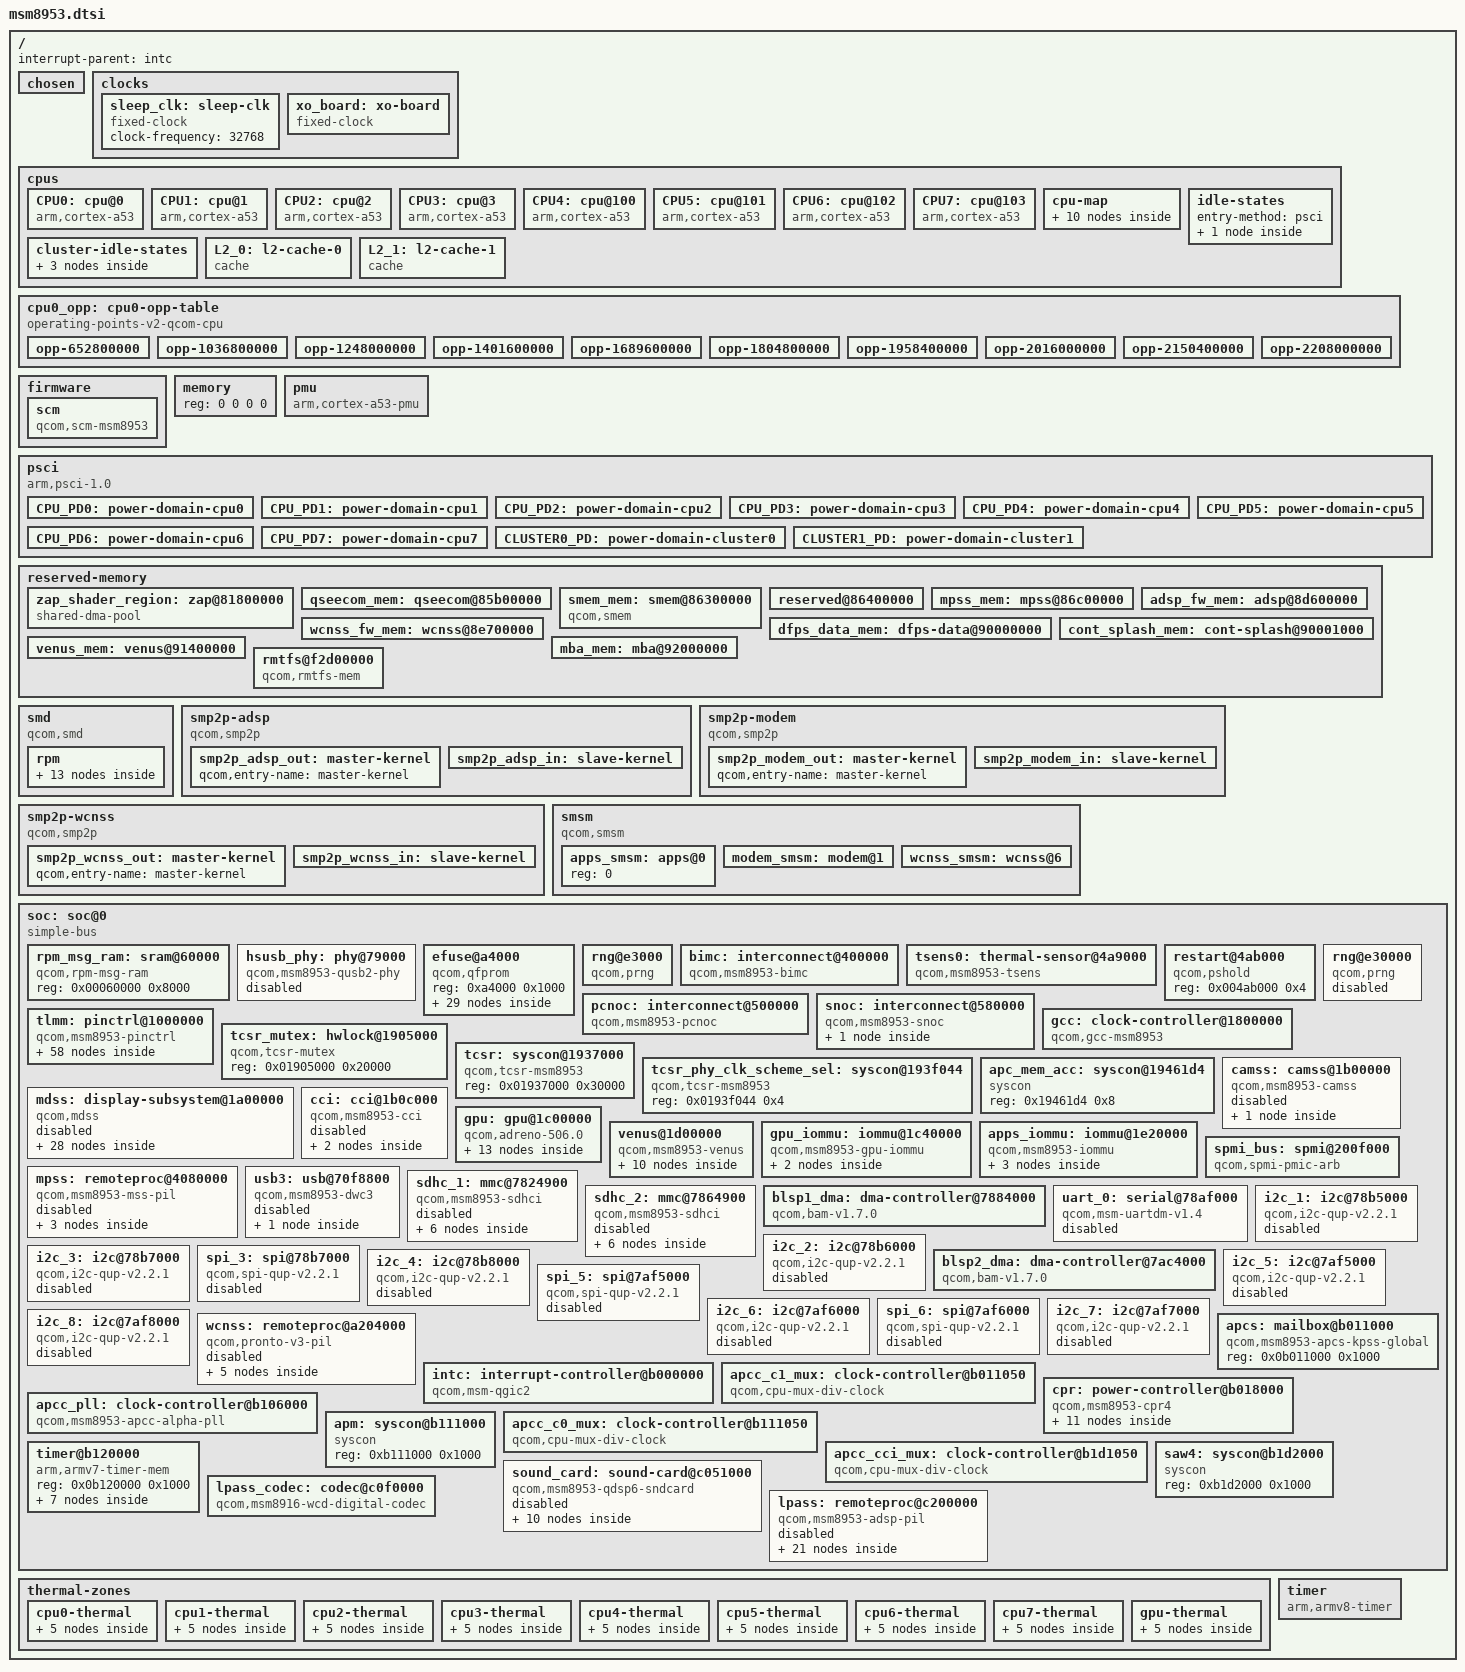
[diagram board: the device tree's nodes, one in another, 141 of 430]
// SPDX-License-Identifier: BSD-3-Clause
/* Copyright (c) 2022, The Linux Foundation. All rights reserved. */

#include <dt-bindings/clock/qcom,gcc-msm8953.h>
#include <dt-bindings/clock/qcom,rpmcc.h>
#include <dt-bindings/gpio/gpio.h>
#include <dt-bindings/interconnect/qcom,msm8953.h>
#include <dt-bindings/interrupt-controller/arm-gic.h>
#include <dt-bindings/power/qcom-rpmpd.h>
#include <dt-bindings/soc/qcom,apr.h>
#include <dt-bindings/sound/qcom,q6afe.h>
#include <dt-bindings/sound/qcom,q6asm.h>
#include <dt-bindings/sound/qcom,q6voice.h>
#include <dt-bindings/thermal/thermal.h>

/ {
	interrupt-parent = <&intc>;

	#address-cells = <2>;
	#size-cells = <2>;

	chosen { };

	clocks {
		sleep_clk: sleep-clk {
			compatible = "fixed-clock";
			#clock-cells = <0>;
			clock-frequency = <32768>;
		};

		xo_board: xo-board {
			compatible = "fixed-clock";
			#clock-cells = <0>;
			clock-frequency = <19200000>;
			clock-output-names = "xo";
		};
	};

	cpus {
		#address-cells = <1>;
		#size-cells = <0>;

		CPU0: cpu@0 {
			device_type = "cpu";
			compatible = "arm,cortex-a53";
			reg = <0x0>;
			enable-method = "psci";
			capacity-dmips-mhz = <1024>;
			clocks = <&apcc_pll>;
			clock-names = "cpu";
			operating-points-v2 = <&cpu0_opp>;
			power-domains = <&CPU_PD0>, <&cpr 0>;
			power-domain-names = "psci", "cpr";
			interconnects = <&bimc MAS_APPS_PROC &bimc SLV_EBI>;
			next-level-cache = <&L2_0>;
			#cooling-cells = <2>;
		};

		CPU1: cpu@1 {
			device_type = "cpu";
			compatible = "arm,cortex-a53";
			reg = <0x1>;
			enable-method = "psci";
			capacity-dmips-mhz = <1024>;
			clocks = <&apcc_pll>;
			clock-names = "cpu";
			operating-points-v2 = <&cpu0_opp>;
			power-domains = <&CPU_PD1>, <&cpr 0>;
			power-domain-names = "psci", "cpr";
			interconnects = <&bimc MAS_APPS_PROC &bimc SLV_EBI>;
			next-level-cache = <&L2_0>;
			#cooling-cells = <2>;
		};

		CPU2: cpu@2 {
			device_type = "cpu";
			compatible = "arm,cortex-a53";
			reg = <0x2>;
			enable-method = "psci";
			capacity-dmips-mhz = <1024>;
			clocks = <&apcc_pll>;
			clock-names = "cpu";
			operating-points-v2 = <&cpu0_opp>;
			power-domains = <&CPU_PD2>, <&cpr 0>;
			power-domain-names = "psci", "cpr";
			interconnects = <&bimc MAS_APPS_PROC &bimc SLV_EBI>;
			next-level-cache = <&L2_0>;
			#cooling-cells = <2>;
		};

		CPU3: cpu@3 {
			device_type = "cpu";
			compatible = "arm,cortex-a53";
			reg = <0x3>;
			enable-method = "psci";
			capacity-dmips-mhz = <1024>;
			clocks = <&apcc_pll>;
			clock-names = "cpu";
			operating-points-v2 = <&cpu0_opp>;
			power-domains = <&CPU_PD3>, <&cpr 0>;
			power-domain-names = "psci", "cpr";
			interconnects = <&bimc MAS_APPS_PROC &bimc SLV_EBI>;
			next-level-cache = <&L2_0>;
			#cooling-cells = <2>;
		};

		CPU4: cpu@100 {
			device_type = "cpu";
			compatible = "arm,cortex-a53";
			reg = <0x100>;
			enable-method = "psci";
			capacity-dmips-mhz = <1024>;
			clocks = <&apcc_pll>;
			clock-names = "cpu";
			operating-points-v2 = <&cpu0_opp>;
			power-domains = <&CPU_PD4>, <&cpr 0>;
			power-domain-names = "psci", "cpr";
			interconnects = <&bimc MAS_APPS_PROC &bimc SLV_EBI>;
			next-level-cache = <&L2_1>;
			#cooling-cells = <2>;
		};

		CPU5: cpu@101 {
			device_type = "cpu";
			compatible = "arm,cortex-a53";
			reg = <0x101>;
			enable-method = "psci";
			capacity-dmips-mhz = <1024>;
			clocks = <&apcc_pll>;
			clock-names = "cpu";
			operating-points-v2 = <&cpu0_opp>;
			power-domains = <&CPU_PD5>, <&cpr 0>;
			power-domain-names = "psci", "cpr";
			interconnects = <&bimc MAS_APPS_PROC &bimc SLV_EBI>;
			next-level-cache = <&L2_1>;
			#cooling-cells = <2>;
		};

		CPU6: cpu@102 {
			device_type = "cpu";
			compatible = "arm,cortex-a53";
			reg = <0x102>;
			enable-method = "psci";
			capacity-dmips-mhz = <1024>;
			clocks = <&apcc_pll>;
			clock-names = "cpu";
			operating-points-v2 = <&cpu0_opp>;
			power-domains = <&CPU_PD6>, <&cpr 0>;
			power-domain-names = "psci", "cpr";
			interconnects = <&bimc MAS_APPS_PROC &bimc SLV_EBI>;
			next-level-cache = <&L2_1>;
			#cooling-cells = <2>;
		};

		CPU7: cpu@103 {
			device_type = "cpu";
			compatible = "arm,cortex-a53";
			reg = <0x103>;
			enable-method = "psci";
			capacity-dmips-mhz = <1024>;
			clocks = <&apcc_pll>;
			clock-names = "cpu";
			operating-points-v2 = <&cpu0_opp>;
			power-domains = <&CPU_PD7>, <&cpr 0>;
			power-domain-names = "psci", "cpr";
			interconnects = <&bimc MAS_APPS_PROC &bimc SLV_EBI>;
			next-level-cache = <&L2_1>;
			#cooling-cells = <2>;
		};

		cpu-map {
			cluster0 {
				core0 {
					cpu = <&CPU0>;
				};
				core1 {
					cpu = <&CPU1>;
				};
				core2 {
					cpu = <&CPU2>;
				};
				core3 {
					cpu = <&CPU3>;
				};
			};

			cluster1 {
				core0 {
					cpu = <&CPU4>;
				};
				core1 {
					cpu = <&CPU5>;
				};
				core2 {
					cpu = <&CPU6>;
				};
				core3 {
					cpu = <&CPU7>;
				};
			};
		};

		idle-states {
			entry-method = "psci";

			CPU_PC: cpu-power-collapse {
				compatible = "arm,idle-state";
				idle-state-name = "cpu-pc";
				arm,psci-suspend-param = <0x40000003>;
				entry-latency-us = <90>;
				exit-latency-us = <180>;
				min-residency-us = <400>;
				local-timer-stop;
			};
		};

		cluster-idle-states {
			CLUSTER_RET: cluster-retention {
				compatible = "domain-idle-state";
				idle-state-name = "cluster-ret";
				arm,psci-suspend-param = <0x41000033>;
				entry-latency-us = <120>;
				exit-latency-us = <200>;
				min-residency-us = <1200>;
				local-timer-stop;
			};

			CLUSTER_GDHS: cluster-gdhs {
				compatible = "domain-idle-state";
				idle-state-name = "cluster-gdhs";
				arm,psci-suspend-param = <0x41000043>;
				entry-latency-us = <150>;
				exit-latency-us = <220>;
				min-residency-us = <1800>;
				local-timer-stop;
			};

			CLUSTER_PC: cluster-power-collapse {
				compatible = "domain-idle-state";
				idle-state-name = "cluster-pc";
				arm,psci-suspend-param = <0x41000053>;
				entry-latency-us = <270>;
				exit-latency-us = <430>;
				min-residency-us = <2500>;
				local-timer-stop;
			};
		};

		L2_0: l2-cache-0 {
			compatible = "cache";
			cache-level = <2>;
			cache-unified;
		};

		L2_1: l2-cache-1 {
			compatible = "cache";
			cache-level = <2>;
			cache-unified;
		};
	};

	cpu0_opp: cpu0-opp-table {
		compatible = "operating-points-v2-qcom-cpu";
		nvmem-cells = <&cpu_speed_bin>;
		opp-shared;

		opp-652800000 {
			opp-hz = /bits/ 64 <652800000>;
			opp-supported-hw = <0xC5>;
			required-opps = <&cpr_opp1>;
			opp-suspend;
		};

		opp-1036800000 {
			opp-hz = /bits/ 64 <1036800000>;
			opp-supported-hw = <0xC5>;
			required-opps = <&cpr_opp2>;
		};

		opp-1248000000 {
			opp-hz = /bits/ 64 <1248000000>;
			opp-supported-hw = <0xC5>;
			required-opps = <&cpr_opp3>;
		};

		opp-1401600000 {
			opp-hz = /bits/ 64 <1401600000>;
			opp-supported-hw = <0xC5>;
			required-opps = <&cpr_opp4>;
		};

		opp-1689600000 {
			opp-hz = /bits/ 64 <1689600000>;
			opp-supported-hw = <0xC5>;
			required-opps = <&cpr_opp5>;
		};

		opp-1804800000 {
			opp-hz = /bits/ 64 <1804800000>;
			opp-supported-hw = <0xC5>;
			required-opps = <&cpr_opp6>;
		};

		opp-1958400000 {
			opp-hz = /bits/ 64 <1958400000>;
			opp-supported-hw = <0x85>;
			required-opps = <&cpr_opp7>;
		};

		opp-2016000000 {
			opp-hz = /bits/ 64 <2016000000>;
			opp-supported-hw = <0x85>;
			required-opps = <&cpr_opp8>;
		};

		opp-2150400000 {
			opp-hz = /bits/ 64 <2150400000>;
			opp-supported-hw = <0x81>;
			required-opps = <&cpr_opp9>;
		};

		opp-2208000000 {
			opp-hz = /bits/ 64 <2208000000>;
			opp-supported-hw = <0x81>;
			required-opps = <&cpr_opp10>;
		};
	};

	firmware {
		scm: scm {
			compatible = "qcom,scm-msm8953", "qcom,scm";
			clocks = <&gcc GCC_CRYPTO_CLK>,
				 <&gcc GCC_CRYPTO_AXI_CLK>,
				 <&gcc GCC_CRYPTO_AHB_CLK>;
			clock-names = "core", "bus", "iface";
			#reset-cells = <1>;
		};
	};

	memory {
		device_type = "memory";
		/* We expect the bootloader to fill in the reg */
		reg = <0 0 0 0>;
	};

	pmu {
		compatible = "arm,cortex-a53-pmu";
		interrupts = <GIC_PPI 7 (GIC_CPU_MASK_SIMPLE(8) | IRQ_TYPE_LEVEL_HIGH)>;
	};

	psci {
		compatible = "arm,psci-1.0";
		method = "smc";
		force-psci-domains;

		CPU_PD0: power-domain-cpu0 {
			#power-domain-cells = <0>;
			domain-idle-states = <&CPU_PC>;
			power-domains = <&CLUSTER0_PD>;
		};

		CPU_PD1: power-domain-cpu1 {
			#power-domain-cells = <0>;
			domain-idle-states = <&CPU_PC>;
			power-domains = <&CLUSTER0_PD>;
		};

		CPU_PD2: power-domain-cpu2 {
			#power-domain-cells = <0>;
			domain-idle-states = <&CPU_PC>;
			power-domains = <&CLUSTER0_PD>;
		};

		CPU_PD3: power-domain-cpu3 {
			#power-domain-cells = <0>;
			domain-idle-states = <&CPU_PC>;
			power-domains = <&CLUSTER0_PD>;
		};

		CPU_PD4: power-domain-cpu4 {
			#power-domain-cells = <0>;
			domain-idle-states = <&CPU_PC>;
			power-domains = <&CLUSTER1_PD>;
		};

		CPU_PD5: power-domain-cpu5 {
			#power-domain-cells = <0>;
			domain-idle-states = <&CPU_PC>;
			power-domains = <&CLUSTER1_PD>;
		};

		CPU_PD6: power-domain-cpu6 {
			#power-domain-cells = <0>;
			domain-idle-states = <&CPU_PC>;
			power-domains = <&CLUSTER1_PD>;
		};

		CPU_PD7: power-domain-cpu7 {
			#power-domain-cells = <0>;
			domain-idle-states = <&CPU_PC>;
			power-domains = <&CLUSTER1_PD>;
		};

		CLUSTER0_PD: power-domain-cluster0 {
			#power-domain-cells = <0>;
			domain-idle-states = <&CLUSTER_RET>, <&CLUSTER_GDHS>, <&CLUSTER_PC>;
		};

		CLUSTER1_PD: power-domain-cluster1 {
			#power-domain-cells = <0>;
			domain-idle-states = <&CLUSTER_RET>, <&CLUSTER_GDHS>, <&CLUSTER_PC>;
		};
	};

	reserved-memory {
		#address-cells = <2>;
		#size-cells = <2>;
		ranges;

		zap_shader_region: zap@81800000 {
			compatible = "shared-dma-pool";
			reg = <0x0 0x81800000 0x0 0x2000>;
			no-map;
		};

		qseecom_mem: qseecom@85b00000 {
			reg = <0x0 0x85b00000 0x0 0x800000>;
			no-map;
		};

		smem_mem: smem@86300000 {
			compatible = "qcom,smem";
			reg = <0x0 0x86300000 0x0 0x100000>;
			qcom,rpm-msg-ram = <&rpm_msg_ram>;
			hwlocks = <&tcsr_mutex 3>;
			no-map;
		};

		reserved@86400000 {
			reg = <0x0 0x86400000 0x0 0x400000>;
			no-map;
		};

		mpss_mem: mpss@86c00000 {
			reg = <0x0 0x86c00000 0x0 0x6a00000>;
			no-map;
		};

		adsp_fw_mem: adsp@8d600000 {
			reg = <0x0 0x8d600000 0x0 0x1100000>;
			no-map;
		};

		wcnss_fw_mem: wcnss@8e700000 {
			reg = <0x0 0x8e700000 0x0 0x700000>;
			no-map;
		};

		dfps_data_mem: dfps-data@90000000 {
			reg = <0 0x90000000 0 0x1000>;
			no-map;
		};

		cont_splash_mem: cont-splash@90001000 {
			reg = <0x0 0x90001000 0x0 0x13ff000>;
			no-map;
		};

		venus_mem: venus@91400000 {
			reg = <0x0 0x91400000 0x0 0x700000>;
			no-map;
		};

		mba_mem: mba@92000000 {
			reg = <0x0 0x92000000 0x0 0x100000>;
			no-map;
		};

		rmtfs@f2d00000 {
			compatible = "qcom,rmtfs-mem";
			reg = <0x0 0xf2d00000 0x0 0x180000>;
			no-map;

			qcom,client-id = <1>;
		};
	};

	smd {
		compatible = "qcom,smd";

		rpm {
			interrupts = <GIC_SPI 168 IRQ_TYPE_EDGE_RISING>;
			qcom,ipc = <&apcs 8 0>;
			qcom,smd-edge = <15>;

			rpm_requests: rpm-requests {
				compatible = "qcom,rpm-msm8953";
				qcom,smd-channels = "rpm_requests";

				rpmcc: clock-controller {
					compatible = "qcom,rpmcc-msm8953", "qcom,rpmcc";
					clocks = <&xo_board>;
					clock-names = "xo";
					#clock-cells = <1>;
				};

				rpmpd: power-controller {
					compatible = "qcom,msm8953-rpmpd";
					#power-domain-cells = <1>;
					operating-points-v2 = <&rpmpd_opp_table>;

					rpmpd_opp_table: opp-table {
						compatible = "operating-points-v2";

						rpmpd_opp_ret: opp1 {
							opp-level = <RPM_SMD_LEVEL_RETENTION>;
						};

						rpmpd_opp_ret_plus: opp2 {
							opp-level = <RPM_SMD_LEVEL_RETENTION_PLUS>;
						};

						rpmpd_opp_min_svs: opp3 {
							opp-level = <RPM_SMD_LEVEL_MIN_SVS>;
						};

						rpmpd_opp_low_svs: opp4 {
							opp-level = <RPM_SMD_LEVEL_LOW_SVS>;
						};

						rpmpd_opp_svs: opp5 {
							opp-level = <RPM_SMD_LEVEL_SVS>;
						};

						rpmpd_opp_svs_plus: opp6 {
							opp-level = <RPM_SMD_LEVEL_SVS_PLUS>;
						};

						rpmpd_opp_nom: opp7 {
							opp-level = <RPM_SMD_LEVEL_NOM>;
						};

						rpmpd_opp_nom_plus: opp8 {
							opp-level = <RPM_SMD_LEVEL_NOM_PLUS>;
						};

						rpmpd_opp_turbo: opp9 {
							opp-level = <RPM_SMD_LEVEL_TURBO>;
						};
					};
				};
			};
		};
	};

	smp2p-adsp {
		compatible = "qcom,smp2p";
		qcom,smem = <443>, <429>;

		interrupts = <GIC_SPI 291 IRQ_TYPE_EDGE_RISING>;

		mboxes = <&apcs 10>;

		qcom,local-pid = <0>;
		qcom,remote-pid = <2>;

		smp2p_adsp_out: master-kernel {
			qcom,entry-name = "master-kernel";
			#qcom,smem-state-cells = <1>;
		};

		smp2p_adsp_in: slave-kernel {
			qcom,entry-name = "slave-kernel";

			interrupt-controller;
			#interrupt-cells = <2>;
		};
	};

	smp2p-modem {
		compatible = "qcom,smp2p";
		qcom,smem = <435>, <428>;

		interrupts = <GIC_SPI 27 IRQ_TYPE_EDGE_RISING>;

		qcom,ipc = <&apcs 8 14>;

		qcom,local-pid = <0>;
		qcom,remote-pid = <1>;

		smp2p_modem_out: master-kernel {
			qcom,entry-name = "master-kernel";

			#qcom,smem-state-cells = <1>;
		};

		smp2p_modem_in: slave-kernel {
			qcom,entry-name = "slave-kernel";

			interrupt-controller;
			#interrupt-cells = <2>;
		};
	};

	smp2p-wcnss {
		compatible = "qcom,smp2p";
		qcom,smem = <451>, <431>;

		interrupts = <GIC_SPI 143 IRQ_TYPE_EDGE_RISING>;

		qcom,ipc = <&apcs 8 18>;

		qcom,local-pid = <0>;
		qcom,remote-pid = <4>;

		smp2p_wcnss_out: master-kernel {
			qcom,entry-name = "master-kernel";

			#qcom,smem-state-cells = <1>;
		};

		smp2p_wcnss_in: slave-kernel {
			qcom,entry-name = "slave-kernel";

			interrupt-controller;
			#interrupt-cells = <2>;
		};
	};

	smsm {
		compatible = "qcom,smsm";

		#address-cells = <1>;
		#size-cells = <0>;

		qcom,ipc-1 = <&apcs 8 13>;
		qcom,ipc-3 = <&apcs 8 19>;

		apps_smsm: apps@0 {
			reg = <0>;

			#qcom,smem-state-cells = <1>;
		};

		modem_smsm: modem@1 {
			reg = <1>;
			interrupts = <GIC_SPI 26 IRQ_TYPE_EDGE_RISING>;

			interrupt-controller;
			#interrupt-cells = <2>;
		};

		wcnss_smsm: wcnss@6 {
			reg = <6>;
			interrupts = <GIC_SPI 144 IRQ_TYPE_EDGE_RISING>;

			interrupt-controller;
			#interrupt-cells = <2>;
		};
	};

	soc: soc@0 {
		#address-cells = <1>;
		#size-cells = <1>;
		ranges = <0 0 0 0xffffffff>;
		compatible = "simple-bus";

		rpm_msg_ram: sram@60000 {
			compatible = "qcom,rpm-msg-ram";
			reg = <0x00060000 0x8000>;
		};

		hsusb_phy: phy@79000 {
			compatible = "qcom,msm8953-qusb2-phy";
			reg = <0x00079000 0x180>;
			#phy-cells = <0>;

			clocks = <&gcc GCC_USB_PHY_CFG_AHB_CLK>,
				 <&gcc GCC_QUSB_REF_CLK>;
			clock-names = "cfg_ahb", "ref";

			qcom,tcsr-syscon = <&tcsr_phy_clk_scheme_sel>;

			resets = <&gcc GCC_QUSB2_PHY_BCR>;

			status = "disabled";
		};

		efuse@a4000 {
			compatible = "qcom,qfprom";
			reg = <0xa4000 0x1000>;
			#address-cells = <1>;
			#size-cells = <1>;

			cpu_speed_bin: cpu_speed_bin@124 {
				reg = <0x125 1>;
				bits = <0 3>;
			};

			cpr_efuse_revision: fusing_rev@23c {
				reg = <0x23e 1>;
				bits = <5 3>;
			};

			cpr_efuse_ring1: ring1@248 {
				reg = <0x248 1>;
				bits = <0 4>;
			};

			cpr_efuse_ring2: ring2@248 {
				reg = <0x248 1>;
				bits = <4 4>;
			};

			cpr_efuse_ring3: ring3@249 {
				reg = <0x249 1>;
				bits = <0 4>;
			};

			cpr_efuse_ring4: ring4@249 {
				reg = <0x249 1>;
				bits = <4 4>;
			};

			cpr_efuse_ring5: ring5@24a {
				reg = <0x24a 1>;
				bits = <0 4>;
			};

			cpr_efuse_ring6: ring6@24a {
				reg = <0x24a 1>;
				bits = <4 4>;
			};

			cpr_efuse_ring7: ring7@24b {
				reg = <0x24b 1>;
				bits = <4 4>;
			};

			cpr_efuse_init_voltage1: ivoltage1@238 {
				reg = <0x238 2>;
				bits = <6 6>;
			};

			cpr_efuse_init_voltage2: ivoltage2@239 {
				reg = <0x239 2>;
				bits = <4 6>;
			};

			cpr_efuse_init_voltage3: ivoltage3@23a {
				reg = <0x23a 1>;
				bits = <2 6>;
			};

			cpr_efuse_init_voltage4: ivoltage4@23b {
				reg = <0x23b 1>;
				bits = <0 6>;
			};

			cpr_efuse_init_voltage5: ivoltage5@250 {
				reg = <0x250 1>;
				bits = <0 6>;
			};

			cpr_efuse_init_voltage6: ivoltage6@250 {
				reg = <0x250 2>;
				bits = <6 6>;
			};

			cpr_efuse_init_voltage7: ivoltage7@252 {
				reg = <0x252 1>;
				bits = <2 6>;
			};

			cpr_efuse_quot1: quot1@241 {
				reg = <0x241 2>;
				bits = <0 12>;
			};

			cpr_efuse_quot2: quot2@242 {
				reg = <0x242 2>;
				bits = <4 12>;
			};

			cpr_efuse_quot3: quot3@244 {
				reg = <0x244 2>;
				bits = <0 12>;
			};

			cpr_efuse_quot4: quot4@245 {
				reg = <0x245 2>;
				bits = <4 12>;
			};

			cpr_efuse_quot5: quot5@259 {
				reg = <0x259 4>;
				bits = <0 12>;
			};

			cpr_efuse_quot6: quot6@25a {
				reg = <0x25a 2>;
				bits = <4 12>;
			};

			cpr_efuse_quot7: quot7@25d {
				reg = <0x25d 2>;
				bits = <4 12>;
			};

			cpr_efuse_quot_offset1: qoffset1@23c {
				reg = <0x23c 1>;
				bits = <0 7>;
			};

			cpr_efuse_quot_offset2: qoffset2@23c {
				reg = <0x23c 2>;
				bits = <7 7>;
			};

			cpr_efuse_quot_offset3: qoffset3@23d {
				reg = <0x23d 2>;
				bits = <6 7>;
			};

			cpr_efuse_quot_offset4: qoffset4@253 {
				reg = <0x253 1>;
				bits = <0 7>;
			};

			cpr_efuse_quot_offset5: qoffset5@254 {
				reg = <0x254 1>;
				bits = <0 7>;
			};

			cpr_efuse_quot_offset6: qoffset6@255 {
				reg = <0x255 1>;
				bits = <0 7>;
			};
		};

		rng@e3000 {
			compatible = "qcom,prng";
			reg = <0x000e3000 0x1000>;
			clocks = <&gcc GCC_PRNG_AHB_CLK>;
			clock-names = "core";
		};

		bimc: interconnect@400000 {
			compatible = "qcom,msm8953-bimc";
			reg = <0x400000 0x5a000>;

			clock-names = "bus", "bus_a";
			clocks = <&rpmcc RPM_SMD_BIMC_CLK>,
				 <&rpmcc RPM_SMD_BIMC_A_CLK>;

			#interconnect-cells = <1>;
		};

		tsens0: thermal-sensor@4a9000 {
			compatible = "qcom,msm8953-tsens", "qcom,tsens-v2";
			reg = <0x004a9000 0x1000>, /* TM */
			      <0x004a8000 0x1000>; /* SROT */
			#qcom,sensors = <16>;
			interrupts = <GIC_SPI 184 IRQ_TYPE_LEVEL_HIGH>,
				     <GIC_SPI 314 IRQ_TYPE_LEVEL_HIGH>;
			interrupt-names = "uplow", "critical";
			#thermal-sensor-cells = <1>;
		};

		restart@4ab000 {
			compatible = "qcom,pshold";
			reg = <0x004ab000 0x4>;
		};

		pcnoc: interconnect@500000 {
			compatible = "qcom,msm8953-pcnoc";
			reg = <0x500000 0x12080>;

			clock-names = "bus", "bus_a", "pcnoc_usb3_axi";
			clocks = <&rpmcc RPM_SMD_PCNOC_CLK>,
				 <&rpmcc RPM_SMD_PCNOC_A_CLK>,
				 <&gcc GCC_PCNOC_USB3_AXI_CLK>;

			#interconnect-cells = <1>;
		};

		snoc: interconnect@580000 {
			compatible = "qcom,msm8953-snoc";
			reg = <0x580000 0x16080>;

			clock-names = "bus", "bus_a";
			clocks = <&rpmcc RPM_SMD_SNOC_CLK>,
				 <&rpmcc RPM_SMD_SNOC_A_CLK>;

			#interconnect-cells = <1>;

			snoc_mm: interconnect {
				compatible = "qcom,msm8953-snoc-mm";

				clock-names = "bus", "bus_a";
				clocks = <&rpmcc RPM_SMD_SYSMMNOC_CLK>,
					 <&rpmcc RPM_SMD_SYSMMNOC_A_CLK>;

				#interconnect-cells = <1>;
			};
		};

		rng@e30000 {
			status = "disabled";
			compatible = "qcom,prng";
			reg = <0x000e3000 0x1000>;
			clocks = <&gcc GCC_PRNG_AHB_CLK>;
			clock-names = "core";
		};

		tlmm: pinctrl@1000000 {
			compatible = "qcom,msm8953-pinctrl";
			reg = <0x01000000 0x300000>;
			interrupts = <GIC_SPI 208 IRQ_TYPE_LEVEL_HIGH>;
			gpio-controller;
			gpio-ranges = <&tlmm 0 0 142>;
			#gpio-cells = <2>;
			interrupt-controller;
			#interrupt-cells = <2>;

			uart_console_active: uart-console-active-state {
				pins = "gpio4", "gpio5";
				function = "blsp_uart2";
				drive-strength = <2>;
				bias-disable;
			};

			uart_console_sleep: uart-console-sleep-state {
				pins = "gpio4", "gpio5";
				function = "blsp_uart2";
				drive-strength = <2>;
				bias-pull-down;
			};

			cci0_default: cci0-pins {
				pins = "gpio29", "gpio30";
				function = "cci_i2c";
				drive-strength = <2>;
				bias-disable;
			};

			cci1_default: cci1-pins {
				pins = "gpio31", "gpio32";
				function = "cci_i2c";
				drive-strength = <2>;
				bias-disable;
			};

			camss_mclk0_default: camss-mclk0-pins {
				pins = "gpio26";
				function = "cam_mclk";
				drive-strength = <2>;
				bias-disable;
			};

			camss_mclk1_default: camss-mclk1-pins {
				pins = "gpio27";
				function = "cam_mclk";
				drive-strength = <2>;
				bias-disable;
			};

			camss_mclk2_default: camss-mclk2-pins {
				pins = "gpio28";
				function = "cam_mclk";
				drive-strength = <2>;
				bias-disable;
			};

			mdss_te_default: mdss-te-pins {
				pins = "gpio24";
				function = "mdp_vsync";
				drive-strength = <2>;
				bias-pull-down;
			};

			sdc1_clk_on: sdc1-clk-on-state {
				pins = "sdc1_clk";
				bias-disable;
				drive-strength = <16>;
			};

			sdc1_clk_off: sdc1-clk-off-state {
				pins = "sdc1_clk";
				bias-disable;
				drive-strength = <2>;
			};

			sdc1_cmd_on: sdc1-cmd-on-state {
				pins = "sdc1_cmd";
				bias-disable;
				drive-strength = <10>;
			};

			sdc1_cmd_off: sdc1-cmd-off-state {
				pins = "sdc1_cmd";
				bias-disable;
				drive-strength = <2>;
			};

			sdc1_data_on: sdc1-data-on-state {
				pins = "sdc1_data";
				bias-pull-up;
				drive-strength = <10>;
			};

			sdc1_data_off: sdc1-data-off-state {
				pins = "sdc1_data";
				bias-pull-up;
				drive-strength = <2>;
			};

			sdc1_rclk_on: sdc1-rclk-on-state {
				pins = "sdc1_rclk";
				bias-pull-down;
			};

			sdc1_rclk_off: sdc1-rclk-off-state {
				pins = "sdc1_rclk";
				bias-pull-down;
			};

			sdc2_clk_on: sdc2-clk-on-state {
				pins = "sdc2_clk";
				drive-strength = <16>;
				bias-disable;
			};

			sdc2_clk_off: sdc2-clk-off-state {
				pins = "sdc2_clk";
				bias-disable;
				drive-strength = <2>;
			};

			sdc2_cmd_on: sdc2-cmd-on-state {
				pins = "sdc2_cmd";
				bias-pull-up;
				drive-strength = <10>;
			};

			sdc2_cmd_off: sdc2-cmd-off-state {
				pins = "sdc2_cmd";
				bias-pull-up;
				drive-strength = <2>;
			};

			sdc2_data_on: sdc2-data-on-state {
				pins = "sdc2_data";
				bias-pull-up;
				drive-strength = <10>;
			};

			sdc2_data_off: sdc2-data-off-state {
				pins = "sdc2_data";
				bias-pull-up;
				drive-strength = <2>;
			};

			sdc2_cd_on: cd-on-state {
				pins = "gpio133";
				function = "gpio";
				drive-strength = <2>;
				bias-pull-up;
			};

			sdc2_cd_off: cd-off-state {
				pins = "gpio133";
				function = "gpio";
				drive-strength = <2>;
				bias-disable;
			};

			gpio_key_default: gpio-key-default-state {
				pins = "gpio85";
				function = "gpio";
				drive-strength = <2>;
				bias-pull-up;
			};

			i2c_1_default: i2c-1-default-state {
				pins = "gpio2", "gpio3";
				function = "blsp_i2c1";
				drive-strength = <2>;
				bias-disable;
			};

			i2c_1_sleep: i2c-1-sleep-state {
				pins = "gpio2", "gpio3";
				function = "gpio";
				drive-strength = <2>;
				bias-disable;
			};

			i2c_2_default: i2c-2-default-state {
				pins = "gpio6", "gpio7";
				function = "blsp_i2c2";
				drive-strength = <2>;
				bias-disable;
			};

			i2c_2_sleep: i2c-2-sleep-state {
				pins = "gpio6", "gpio7";
				function = "gpio";
				drive-strength = <2>;
				bias-disable;
			};

			i2c_3_default: i2c-3-default-state {
				pins = "gpio10", "gpio11";
				function = "blsp_i2c3";
				drive-strength = <2>;
				bias-disable;
			};

			i2c_3_sleep: i2c-3-sleep-state {
				pins = "gpio10", "gpio11";
				function = "gpio";
				drive-strength = <2>;
				bias-disable;
			};

			i2c_4_default: i2c-4-default-state {
				pins = "gpio14", "gpio15";
				function = "blsp_i2c4";
				drive-strength = <2>;
				bias-disable;
			};

			i2c_4_sleep: i2c-4-sleep-state {
				pins = "gpio14", "gpio15";
				function = "gpio";
				drive-strength = <2>;
				bias-disable;
			};

			i2c_5_default: i2c-5-default-state {
				pins = "gpio18", "gpio19";
				function = "blsp_i2c5";
				drive-strength = <2>;
				bias-disable;
			};

			i2c_5_sleep: i2c-5-sleep-state {
				pins = "gpio18", "gpio19";
				function = "gpio";
				drive-strength = <2>;
				bias-disable;
			};

			i2c_6_default: i2c-6-default-state {
				pins = "gpio22", "gpio23";
				function = "blsp_i2c6";
				drive-strength = <2>;
				bias-disable;
			};

			i2c_6_sleep: i2c-6-sleep-state {
				pins = "gpio22", "gpio23";
				function = "gpio";
				drive-strength = <2>;
				bias-disable;
			};

			i2c_7_default: i2c-7-default-state {
				pins = "gpio135", "gpio136";
				function = "blsp_i2c7";
				drive-strength = <2>;
				bias-disable;
			};

			i2c_7_sleep: i2c-7-sleep-state {
				pins = "gpio135", "gpio136";
				function = "gpio";
				drive-strength = <2>;
				bias-disable;
			};

			i2c_8_default: i2c-8-default-state {
				pins = "gpio98", "gpio99";
				function = "blsp_i2c8";
				drive-strength = <2>;
				bias-disable;
			};

			i2c_8_sleep: i2c-8-sleep-state {
				pins = "gpio98", "gpio99";
				function = "gpio";
				drive-strength = <2>;
				bias-disable;
			};

			spi_3_default: spi-3-default-state {
				pins = "gpio10", "gpio11";
				function = "blsp_spi3";
				drive-strength = <2>;
				bias-disable;
			};

			spi_3_sleep: spi-3-sleep-state {
				pins = "gpio10", "gpio11";
				function = "gpio";
				drive-strength = <2>;
				bias-disable;
			};

			spi_5_default: spi-5-default-state {
				pins = "gpio18", "gpio19";
				function = "blsp_spi5";
				drive-strength = <2>;
				bias-disable;
			};

			spi_5_sleep: spi-5-sleep-state {
				pins = "gpio18", "gpio19";
				function = "gpio";
				drive-strength = <2>;
				bias-disable;
			};

			spi_6_default: spi-6-default-state {
				pins = "gpio22", "gpio23";
				function = "blsp_spi6";
				drive-strength = <2>;
				bias-disable;
			};

			spi_6_sleep: spi-6-sleep-state {
				pins = "gpio22", "gpio23";
				function = "gpio";
				drive-strength = <2>;
				bias-disable;
			};

			wcnss_pin_a: wcnss-active-state {

				wcss-wlan2-pins {
					pins = "gpio76";
					function = "wcss_wlan2";
					drive-strength = <6>;
					bias-pull-up;
				};

				wcss-wlan1-pins {
					pins = "gpio77";
					function = "wcss_wlan1";
					drive-strength = <6>;
					bias-pull-up;
				};

				wcss-wlan0-pins {
					pins = "gpio78";
					function = "wcss_wlan0";
					drive-strength = <6>;
					bias-pull-up;
				};

				wcss-wlan-pins {
					pins = "gpio79", "gpio80";
					function = "wcss_wlan";
					drive-strength = <6>;
					bias-pull-up;
				};
			};

			cdc_pdm_lines_2_act: pdm-lines-2-on-pins {
					pins = "gpio70", "gpio71", "gpio72";
					function = "cdc_pdm0";
					drive-strength = <8>;
			};

			cdc_pdm_lines_2_sus: pdm-lines-2-off-pins {
					pins = "gpio70", "gpio71", "gpio72";
					function = "cdc_pdm0";
					drive-strength = <2>;
					bias-disable;
			};

			cdc_pdm_lines_act: pdm-lines-on-pins {
					pins = "gpio69", "gpio73", "gpio74";
					function = "cdc_pdm0";
					drive-strength = <8>;
			};
			cdc_pdm_lines_sus: pdm-lines-off-pins {
					pins = "gpio69", "gpio73", "gpio74";
					function = "cdc_pdm0";
					drive-strength = <2>;
					bias-disable;
			};

			cdc_pdm_comp_lines_act: pdm-comp-lines-on-pins {
					pins = "gpio67", "gpio68";
					function = "cdc_pdm0";
					drive-strength = <8>;
			};

			cdc_pdm_comp_lines_sus: pdm-comp-lines-off-pins {
					pins = "gpio67", "gpio68";
					function = "cdc_pdm0";
					drive-strength = <2>;
					bias-disable;
			};
		};

		gcc: clock-controller@1800000 {
			compatible = "qcom,gcc-msm8953";
			reg = <0x01800000 0x80000>;
			#clock-cells = <1>;
			#reset-cells = <1>;
			#power-domain-cells = <1>;
			clocks = <&rpmcc RPM_SMD_XO_CLK_SRC>,
				 <&sleep_clk>,
				 <&dsi0_phy 1>,
				 <&dsi0_phy 0>,
				 <&dsi1_phy 1>,
				 <&dsi1_phy 0>;
			clock-names = "xo",
				      "sleep",
				      "dsi0pll",
				      "dsi0pllbyte",
				      "dsi1pll",
				      "dsi1pllbyte";

			power-domains = <&rpmpd MSM8953_VDDCX>;
		};

		tcsr_mutex: hwlock@1905000 {
			compatible = "qcom,tcsr-mutex";
			reg = <0x01905000 0x20000>;
			#hwlock-cells = <1>;
		};

		tcsr: syscon@1937000 {
			compatible = "qcom,tcsr-msm8953", "syscon";
			reg = <0x01937000 0x30000>;
		};

		tcsr_phy_clk_scheme_sel: syscon@193f044 {
			compatible = "qcom,tcsr-msm8953", "syscon";
			reg = <0x0193f044 0x4>;
		};

		apc_mem_acc: syscon@19461d4 {
			compatible = "syscon";
			reg = <0x19461d4 0x8>;
		};

		mdss: display-subsystem@1a00000 {
			compatible = "qcom,mdss";

			reg = <0x01a00000 0x1000>,
			      <0x01ab0000 0x1040>;
			reg-names = "mdss_phys",
				    "vbif_phys";

			power-domains = <&gcc MDSS_GDSC>;
			interrupts = <GIC_SPI 72 IRQ_TYPE_LEVEL_HIGH>;

			interrupt-controller;
			#interrupt-cells = <1>;

			interconnects = <&snoc_mm MAS_MDP &bimc SLV_EBI>,
					<&bimc MAS_APPS_PROC &pcnoc SLV_DISP_SS_CFG>;
			interconnect-names = "mdp0-mem", "cpu-cfg";

			clocks = <&gcc GCC_MDSS_AHB_CLK>,
				 <&gcc GCC_MDSS_AXI_CLK>,
				 <&gcc GCC_MDSS_VSYNC_CLK>,
				 <&gcc GCC_MDSS_MDP_CLK>;
			clock-names = "iface",
				      "bus",
				      "vsync",
				      "core";

			resets = <&gcc GCC_MDSS_BCR>;

			#address-cells = <1>;
			#size-cells = <1>;
			ranges;

			status = "disabled";

			mdp: display-controller@1a01000 {
				compatible = "qcom,msm8953-mdp5", "qcom,mdp5";
				reg = <0x01a01000 0x89000>;
				reg-names = "mdp_phys";

				interrupt-parent = <&mdss>;
				interrupts = <0>;

				power-domains = <&gcc MDSS_GDSC>;

				clocks = <&gcc GCC_MDSS_AHB_CLK>,
					 <&gcc GCC_MDSS_AXI_CLK>,
					 <&gcc GCC_MDSS_MDP_CLK>,
					 <&gcc GCC_MDSS_VSYNC_CLK>;
				clock-names = "iface",
					      "bus",
					      "core",
					      "vsync";

				iommus = <&apps_iommu 0x15>;

				ports {
					#address-cells = <1>;
					#size-cells = <0>;

					port@0 {
						reg = <0>;
						mdp5_intf1_out: endpoint {
							remote-endpoint = <&dsi0_in>;
						};
					};

					port@1 {
						reg = <1>;
						mdp5_intf2_out: endpoint {
							remote-endpoint = <&dsi1_in>;
						};
					};
				};
			};

			dsi0: dsi@1a94000 {
				compatible = "qcom,msm8953-dsi-ctrl", "qcom,mdss-dsi-ctrl";
				reg = <0x01a94000 0x400>;
				reg-names = "dsi_ctrl";

				interrupt-parent = <&mdss>;
				interrupts = <4>;

				assigned-clocks = <&gcc BYTE0_CLK_SRC>,
						  <&gcc PCLK0_CLK_SRC>;
				assigned-clock-parents = <&dsi0_phy 0>,
							 <&dsi0_phy 1>;

				clocks = <&gcc GCC_MDSS_MDP_CLK>,
					 <&gcc GCC_MDSS_AHB_CLK>,
					 <&gcc GCC_MDSS_AXI_CLK>,
					 <&gcc GCC_MDSS_BYTE0_CLK>,
					 <&gcc GCC_MDSS_PCLK0_CLK>,
					 <&gcc GCC_MDSS_ESC0_CLK>;
				clock-names = "mdp_core",
					      "iface",
					      "bus",
					      "byte",
					      "pixel",
					      "core";

				phys = <&dsi0_phy>;

				operating-points-v2 = <&dsi0_opp_table>;
				power-domains = <&rpmpd MDSS_GDSC>;

				#address-cells = <1>;
				#size-cells = <0>;

				status = "disabled";

				ports {
					#address-cells = <1>;
					#size-cells = <0>;

					port@0 {
						reg = <0>;
						dsi0_in: endpoint {
							remote-endpoint = <&mdp5_intf1_out>;
						};
					};

					port@1 {
						reg = <1>;
						dsi0_out: endpoint {
						};
					};
				};

				dsi0_opp_table: dsi-opp-table {
					compatible = "operating-points-v2";

						opp-131250000 {
								opp-hz = /bits/ 64 <131250000>;
								required-opps = <&rpmpd_opp_low_svs>;
						};

						opp-210000000 {
								opp-hz = /bits/ 64 <210000000>;
								required-opps = <&rpmpd_opp_svs>;
						};

						opp-262500000 {
								opp-hz = /bits/ 64 <262500000>;
								required-opps = <&rpmpd_opp_nom>;
						};
				};
			};

			dsi0_phy: phy@1a94400 {
				compatible = "qcom,dsi-phy-14nm-8953";
				reg = <0x01a94400 0x100>,
				      <0x01a94500 0x300>,
				      <0x01a94800 0x188>;
				reg-names = "dsi_phy",
					    "dsi_phy_lane",
					    "dsi_pll";

				#clock-cells = <1>;
				#phy-cells = <0>;

				clocks = <&gcc GCC_MDSS_AHB_CLK>, <&rpmcc RPM_SMD_XO_CLK_SRC>;
				clock-names = "iface", "ref";

				status = "disabled";
			};

			dsi1: dsi@1a96000 {
				compatible = "qcom,msm8953-dsi-ctrl", "qcom,mdss-dsi-ctrl";
				reg = <0x01a96000 0x400>;
				reg-names = "dsi_ctrl";

				interrupt-parent = <&mdss>;
				interrupts = <5>;

				assigned-clocks = <&gcc BYTE1_CLK_SRC>,
						  <&gcc PCLK1_CLK_SRC>;
				assigned-clock-parents = <&dsi1_phy 0>,
							 <&dsi1_phy 1>;

				clocks = <&gcc GCC_MDSS_MDP_CLK>,
					 <&gcc GCC_MDSS_AHB_CLK>,
					 <&gcc GCC_MDSS_AXI_CLK>,
					 <&gcc GCC_MDSS_BYTE1_CLK>,
					 <&gcc GCC_MDSS_PCLK1_CLK>,
					 <&gcc GCC_MDSS_ESC1_CLK>;
				clock-names = "mdp_core",
					      "iface",
					      "bus",
					      "byte",
					      "pixel",
					      "core";

				phys = <&dsi1_phy>;

				operating-points-v2 = <&dsi1_opp_table>;
				power-domains = <&rpmpd MDSS_GDSC>;

				status = "disabled";

				ports {
					#address-cells = <1>;
					#size-cells = <0>;

					port@0 {
						reg = <0>;
						dsi1_in: endpoint {
							remote-endpoint = <&mdp5_intf2_out>;
						};
					};

					port@1 {
						reg = <1>;
						dsi1_out: endpoint {
						};
					};
				};

				dsi1_opp_table: dsi-opp-table {
					compatible = "operating-points-v2";

						opp-131250000 {
								opp-hz = /bits/ 64 <131250000>;
								required-opps = <&rpmpd_opp_low_svs>;
						};

						opp-210000000 {
								opp-hz = /bits/ 64 <210000000>;
								required-opps = <&rpmpd_opp_svs>;
						};

						opp-262500000 {
								opp-hz = /bits/ 64 <262500000>;
								required-opps = <&rpmpd_opp_nom>;
						};
				};
			};

			dsi1_phy: phy@1a96400 {
				compatible = "qcom,dsi-phy-14nm-8953";
				reg = <0x01a96400 0x100>,
				      <0x01a96500 0x300>,
				      <0x01a96800 0x188>;
				reg-names = "dsi_phy",
					    "dsi_phy_lane",
					    "dsi_pll";

				#clock-cells = <1>;
				#phy-cells = <0>;

				clocks = <&gcc GCC_MDSS_AHB_CLK>, <&rpmcc RPM_SMD_XO_CLK_SRC>;
				clock-names = "iface", "ref";

				status = "disabled";
			};
		};

		camss: camss@1b00000 {
			compatible = "qcom,msm8953-camss";
			reg = <0x1b34000 0x1000>,
			      <0x1b00030 0x4>,
			      <0x1b35000 0x1000>,
			      <0x1b00038 0x4>,
			      <0x1b36000 0x1000>,
			      <0x1b00040 0x4>,
			      <0x1b30000 0x100>,
			      <0x1b30400 0x100>,
			      <0x1b30800 0x100>,
			      <0x1b31000 0x500>,
			      <0x1b00020 0x10>,
			      <0x1b10000 0x1000>,
			      <0x1b14000 0x1000>;
			reg-names = "csiphy0",
				    "csiphy0_clk_mux",
				    "csiphy1",
				    "csiphy1_clk_mux",
				    "csiphy2",
				    "csiphy2_clk_mux",
				    "csid0",
				    "csid1",
				    "csid2",
				    "ispif",
				    "csi_clk_mux",
				    "vfe0",
				    "vfe1";
			interrupts = <GIC_SPI 78 IRQ_TYPE_EDGE_RISING>,
				     <GIC_SPI 79 IRQ_TYPE_EDGE_RISING>,
				     <GIC_SPI 315 IRQ_TYPE_EDGE_RISING>,
				     <GIC_SPI 51 IRQ_TYPE_EDGE_RISING>,
				     <GIC_SPI 52 IRQ_TYPE_EDGE_RISING>,
				     <GIC_SPI 153 IRQ_TYPE_EDGE_RISING>,
				     <GIC_SPI 55 IRQ_TYPE_EDGE_RISING>,
				     <GIC_SPI 57 IRQ_TYPE_EDGE_RISING>,
				     <GIC_SPI 29 IRQ_TYPE_EDGE_RISING>;
			interrupt-names = "csiphy0",
					  "csiphy1",
					  "csiphy2",
					  "csid0",
					  "csid1",
					  "csid2",
					  "ispif",
					  "vfe0",
					  "vfe1";
			power-domains = <&gcc VFE0_GDSC>,
					<&gcc VFE1_GDSC>;
			clocks = <&gcc GCC_CAMSS_TOP_AHB_CLK>,
				 <&gcc GCC_CAMSS_ISPIF_AHB_CLK>,
				 <&gcc GCC_CAMSS_MICRO_AHB_CLK>,
				 <&gcc GCC_CAMSS_CSI0PHYTIMER_CLK>,
				 <&gcc GCC_CAMSS_CSI1PHYTIMER_CLK>,
				 <&gcc GCC_CAMSS_CSI2PHYTIMER_CLK>,
				 <&gcc GCC_CAMSS_CSI0_AHB_CLK>,
				 <&gcc GCC_CAMSS_CSI0_CLK>,
				 <&gcc GCC_CAMSS_CSI0PHY_CLK>,
				 <&gcc GCC_CAMSS_CSI0PIX_CLK>,
				 <&gcc GCC_CAMSS_CSI0RDI_CLK>,
				 <&gcc GCC_CAMSS_CSI1_AHB_CLK>,
				 <&gcc GCC_CAMSS_CSI1_CLK>,
				 <&gcc GCC_CAMSS_CSI1PHY_CLK>,
				 <&gcc GCC_CAMSS_CSI1PIX_CLK>,
				 <&gcc GCC_CAMSS_CSI1RDI_CLK>,
				 <&gcc GCC_CAMSS_CSI2_AHB_CLK>,
				 <&gcc GCC_CAMSS_CSI2_CLK>,
				 <&gcc GCC_CAMSS_CSI2PHY_CLK>,
				 <&gcc GCC_CAMSS_CSI2PIX_CLK>,
				 <&gcc GCC_CAMSS_CSI2RDI_CLK>,
				 <&gcc GCC_CAMSS_AHB_CLK>,
				 <&gcc GCC_CAMSS_VFE0_CLK>,
				 <&gcc GCC_CAMSS_CSI_VFE0_CLK>,
				 <&gcc GCC_CAMSS_VFE0_AHB_CLK>,
				 <&gcc GCC_CAMSS_VFE0_AXI_CLK>,
				 <&gcc GCC_CAMSS_VFE1_CLK>,
				 <&gcc GCC_CAMSS_CSI_VFE1_CLK>,
				 <&gcc GCC_CAMSS_VFE1_AHB_CLK>,
				 <&gcc GCC_CAMSS_VFE1_AXI_CLK>;
			clock-names = "top_ahb",
				      "ispif_ahb",
				      "micro_ahb",
				      "csiphy0_timer",
				      "csiphy1_timer",
				      "csiphy2_timer",
				      "csi0_ahb",
				      "csi0",
				      "csi0_phy",
				      "csi0_pix",
				      "csi0_rdi",
				      "csi1_ahb",
				      "csi1",
				      "csi1_phy",
				      "csi1_pix",
				      "csi1_rdi",
				      "csi2_ahb",
				      "csi2",
				      "csi2_phy",
				      "csi2_pix",
				      "csi2_rdi",
				      "ahb",
				      "vfe0",
				      "csi_vfe0",
				      "vfe0_ahb",
				      "vfe0_axi",
				      "vfe1",
				      "csi_vfe1",
				      "vfe1_ahb",
				      "vfe1_axi";
			iommus = <&apps_iommu 0x14>;

			interconnects = <&snoc_mm MAS_VFE0 &bimc SLV_EBI>,
					<&snoc_mm MAS_VFE1 &bimc SLV_EBI>,
					<&bimc MAS_APPS_PROC &pcnoc SLV_CAMERA_SS_CFG>;
			interconnect-names = "cam_vfe0_mem", "cam_vfe1_mem", "cam_ahb";

			status = "disabled";

			ports {
				#address-cells = <1>;
				#size-cells = <0>;
			};
		};

		cci: cci@1b0c000 {
			compatible = "qcom,msm8953-cci";

			reg = <0x1b0c000 0x1000>;

			interrupts = <GIC_SPI 50 IRQ_TYPE_EDGE_RISING>;

			clocks = <&gcc GCC_CAMSS_TOP_AHB_CLK>,
				 <&gcc GCC_CAMSS_CCI_AHB_CLK>,
				 <&gcc GCC_CAMSS_CCI_CLK>,
				 <&gcc GCC_CAMSS_AHB_CLK>;
			clock-names = "camss_top_ahb",
				      "cci_ahb",
				      "cci",
				      "camss_ahb";

			assigned-clocks = <&gcc GCC_CAMSS_CCI_AHB_CLK>,
					  <&gcc GCC_CAMSS_CCI_CLK>;
			assigned-clock-rates = <80000000>, <19200000>;

			#address-cells = <1>;
			#size-cells = <0>;

			status = "disabled";

			cci_i2c0: i2c-bus@0 {
				reg = <0>;
				clock-frequency = <400000>;
				#address-cells = <1>;
				#size-cells = <0>;
			};

			cci_i2c1: i2c-bus@1 {
				reg = <1>;
				clock-frequency = <400000>;
				#address-cells = <1>;
				#size-cells = <0>;
			};
		};

		gpu: gpu@1c00000 {
			compatible = "qcom,adreno-506.0", "qcom,adreno";

			reg = <0x1c00000 0x40000>;
			reg-names = "kgsl_3d0_reg_memory";

			interrupts = <GIC_SPI 33 IRQ_TYPE_LEVEL_HIGH>;

			clocks = <&gcc GCC_OXILI_GFX3D_CLK>,
				 <&gcc GCC_OXILI_AHB_CLK>,
				 <&gcc GCC_BIMC_GFX_CLK>,
				 <&gcc GCC_BIMC_GPU_CLK>,
				 <&gcc GCC_OXILI_TIMER_CLK>,
				 <&gcc GCC_OXILI_AON_CLK>;

			clock-names = "core",
				      "iface",
				      "mem",
				      "mem_iface",
				      "rbbmtimer",
				      "alwayson";

			power-domains = <&gcc OXILI_GX_GDSC>;
			power-domain-names = "gx";

			nvmem-cells = <&cpu_speed_bin>;
			nvmem-cell-names = "speed_bin";

			interconnects = <&bimc MAS_OXILI &bimc SLV_EBI>,
					<&bimc MAS_APPS_PROC &pcnoc SLV_GPU_CFG>;

			iommus = <&gpu_iommu 0>;

			operating-points-v2 = <&gpu_opp_table>;
			opp-default-hw = <0x2>;

			#cooling-cells = <2>;

			gpu_opp_table: opp-table {
				compatible  ="operating-points-v2";

				opp-200000000 {
					opp-hz = /bits/ 64 <200000000>;
					opp-supported-hw = <0x1ff>;
					opp-avg-kBps = <0>, <(1689600/4)>;
					opp-peak-kBps = <1689600>, <(1689600/2)>;
					required-opps = <&rpmpd_opp_low_svs>;
				};

				opp-266670000 {
					opp-hz = /bits/ 64 <266670000>;
					opp-supported-hw = <0x1ff>;
					opp-avg-kBps = <0>, <(3072000/4)>;
					opp-peak-kBps = <3072000>, <(3072000/2)>;
					required-opps = <&rpmpd_opp_svs>;
				};

				opp-320000000 {
					opp-hz = /bits/ 64 <320000000>;
					opp-supported-hw = <0x1ff>;
					opp-avg-kBps = <0>, <(3379200/4)>;
					opp-peak-kBps = <3379200>, <(3379200/2)>;
					required-opps = <&rpmpd_opp_svs>;
				};

				opp-400000000 {
					opp-hz = /bits/ 64 <400000000>;
					opp-supported-hw = <0x1ff>;
					opp-avg-kBps = <0>, <(5376000/4)>;
					opp-peak-kBps = <5376000>, <(5376000/2)>;
					required-opps = <&rpmpd_opp_svs_plus>;
				};

				opp-460800000 {
					opp-hz = /bits/ 64 <460800000>;
					opp-supported-hw = <0x1ff>;
					opp-avg-kBps = <0>, <(6144000/4)>;
					opp-peak-kBps = <6144000>, <(6144000/2)>;
					required-opps = <&rpmpd_opp_nom>;
				};
				opp-510000000 {
					opp-hz = /bits/ 64 <510000000>;
					opp-supported-hw = <0x1ff>;
					opp-avg-kBps = <0>, <(6451200/4)>;
					opp-peak-kBps = <6451200>, <(6451200/2)>;
					required-opps = <&rpmpd_opp_nom>;
				};

				opp-560000000 {
					opp-hz = /bits/ 64 <560000000>;
					opp-supported-hw = <0x1ff>;
					opp-avg-kBps = <0>, <(6758400/4)>;
					opp-peak-kBps = <6758400>, <(6758400/2)>;
					required-opps = <&rpmpd_opp_nom_plus>;
				};

				opp-600000000 {
					opp-hz = /bits/ 64 <600000000>;
					opp-supported-hw = <0x1ff>;
					opp-avg-kBps = <0>, <(7449600/4)>;
					opp-peak-kBps = <7449600>, <(7449600/2)>;
					required-opps = <&rpmpd_opp_turbo>;
				};

				opp-650000000 {
					opp-hz = /bits/ 64 <650000000>;
					opp-supported-hw = <0x185>;
					opp-avg-kBps = <0>, <(7449600/4)>;
					opp-peak-kBps = <7449600>, <(7449600/2)>;
					required-opps = <&rpmpd_opp_turbo>;
				};

				opp-685000000 {
					opp-hz = /bits/ 64 <685000000>;
					opp-supported-hw = <0x100>;
					opp-avg-kBps = <0>, <(7449600/4)>;
					opp-peak-kBps = <7449600>, <(7449600/2)>;
					required-opps = <&rpmpd_opp_turbo>;
				};

				opp-725000000 {
					opp-hz = /bits/ 64 <725000000>;
					opp-supported-hw = <0x100>;
					opp-avg-kBps = <0>, <(7449600/4)>;
					opp-peak-kBps = <7449600>, <(7449600/2)>;
					required-opps = <&rpmpd_opp_turbo>;
				};
			};

			zap-shader {
				memory-region = <&zap_shader_region>;
				firmware-name = "a506_zap.mdt";
			};
		};

		venus@1d00000 {
			compatible = "qcom,msm8953-venus";
			reg = <0x1d00000 0xff000>;

			interrupts = <GIC_SPI 44 IRQ_TYPE_LEVEL_HIGH>;

			clocks = <&gcc GCC_VENUS0_VCODEC0_CLK>,
				 <&gcc GCC_VENUS0_AHB_CLK>,
				 <&gcc GCC_VENUS0_AXI_CLK>,
				 <&gcc GCC_VENUS0_CORE0_VCODEC0_CLK>;
			clock-names = "core", "iface", "bus", "vcodec0";

			operating-points-v2 = <&venus_opp_table>;

			power-domains = <&gcc VENUS_GDSC>,
					<&rpmpd MSM8953_VDDCX>;
			power-domain-names = "venus", "cx";

			interconnects = <&snoc_mm MAS_VENUS &bimc SLV_EBI>,
					<&bimc MAS_APPS_PROC &pcnoc SLV_VENUS_CFG>;
			interconnect-names = "video-mem", "cpu-cfg";

			iommus = <&apps_iommu 0x16>;

			memory-region = <&venus_mem>;

			video-decoder {
				compatible = "venus-decoder";
				power-domains = <&gcc VENUS_CORE0_GDSC>;
			};

			video-encoder {
				compatible = "venus-encoder";
				power-domains = <&gcc VENUS_CORE0_GDSC>;
			};

			venus_opp_table: venus-opp-table {
				compatible = "operating-points-v2";

				opp-114290000 {
					opp-hz = /bits/ 64 <114290000>;
					required-opps = <&rpmpd_opp_low_svs>;
				};

				opp-228570000 {
					opp-hz = /bits/ 64 <228570000>;
					required-opps = <&rpmpd_opp_svs>;
				};

				opp-310000000 {
					opp-hz = /bits/ 64 <310000000>;
					required-opps = <&rpmpd_opp_svs_plus>;
				};

				opp-360000000 {
					opp-hz = /bits/ 64 <360000000>;
					required-opps = <&rpmpd_opp_nom>;
				};

				opp-400000000 {
					opp-hz = /bits/ 64 <400000000>;
					required-opps = <&rpmpd_opp_nom_plus>;
				};

				opp-465000000 {
					opp-hz = /bits/ 64 <465000000>;
					required-opps = <&rpmpd_opp_turbo>;
				};

				opp-540000000 {
					opp-hz = /bits/ 64 <540000000>;
					required-opps = <&rpmpd_opp_turbo>;
				};
			};
		};

		gpu_iommu: iommu@1c40000 {
			compatible = "qcom,msm8953-gpu-iommu", "qcom,msm-iommu-v1";
			clocks = <&gcc GCC_OXILI_AHB_CLK>,
				 <&gcc GCC_BIMC_GFX_CLK>;
			clock-names = "iface", "bus";

			power-domains = <&gcc OXILI_CX_GDSC>;

			qcom,iommu-secure-id = <18>;
			qcom,use-aarch64-pagetables;

			ranges = <0 0x01c48000 0x8000>;

			#address-cells = <1>;
			#iommu-cells = <1>;
			#size-cells = <1>;

			iommu-ctx@0 { // gfx3d user
				compatible = "qcom,msm-iommu-v2-ns";
				reg = <0x0000 0x1000>;
				interrupts = <GIC_SPI 225 IRQ_TYPE_LEVEL_HIGH>;
			};

			iommu-ctx@2000 { // gfx3d secure
				compatible = "qcom,msm-iommu-v2-sec";
				reg = <0x2000 0x1000>;
				interrupts = <GIC_SPI 233 IRQ_TYPE_LEVEL_HIGH>;
			};
		};

		apps_iommu: iommu@1e20000 {
			compatible = "qcom,msm8953-iommu", "qcom,msm-iommu-v1";
			ranges  = <0 0x01e20000 0x20000>;

			clocks = <&gcc GCC_SMMU_CFG_CLK>,
				 <&gcc GCC_APSS_TCU_ASYNC_CLK>;
			clock-names = "iface", "bus";

			qcom,iommu-secure-id = <17>;

			#address-cells = <1>;
			#iommu-cells = <1>;
			#size-cells = <1>;

			/* VFE */
			iommu-ctx@14000 {
				compatible = "qcom,msm-iommu-v1-ns";
				reg = <0x14000 0x1000>;
				interrupts = <GIC_SPI 111 IRQ_TYPE_LEVEL_HIGH>;
			};

			/* MDP_0 */
			iommu-ctx@15000 {
				compatible = "qcom,msm-iommu-v1-ns";
				reg = <0x15000 0x1000>;
				interrupts = <GIC_SPI 112 IRQ_TYPE_LEVEL_HIGH>;
			};

			/* VENUS_NS */
			iommu-ctx@16000 {
				compatible = "qcom,msm-iommu-v1-ns";
				reg = <0x16000 0x1000>;
				interrupts = <GIC_SPI 113 IRQ_TYPE_LEVEL_HIGH>;
			};
		};

		spmi_bus: spmi@200f000 {
			compatible = "qcom,spmi-pmic-arb";
			reg = <0x0200f000 0x1000>,
			      <0x02400000 0x800000>,
			      <0x02c00000 0x800000>,
			      <0x03800000 0x200000>,
			      <0x0200a000 0x2100>;
			reg-names = "core", "chnls", "obsrvr", "intr", "cnfg";
			interrupt-names = "periph_irq";
			interrupts = <GIC_SPI 190 IRQ_TYPE_LEVEL_HIGH>;
			qcom,ee = <0>;
			qcom,channel = <0>;
			interrupt-controller;

			#interrupt-cells = <4>;
			#address-cells = <2>;
			#size-cells = <0>;
		};

		mpss: remoteproc@4080000 {
			compatible = "qcom,msm8953-mss-pil";
			reg = <0x04080000 0x100>,
			      <0x04020000 0x040>;
			reg-names = "qdsp6", "rmb";

			interrupts-extended = <&intc GIC_SPI 24 IRQ_TYPE_EDGE_RISING>,
					      <&smp2p_modem_in 0 IRQ_TYPE_EDGE_RISING>,
					      <&smp2p_modem_in 1 IRQ_TYPE_EDGE_RISING>,
					      <&smp2p_modem_in 2 IRQ_TYPE_EDGE_RISING>,
					      <&smp2p_modem_in 3 IRQ_TYPE_EDGE_RISING>;
			interrupt-names = "wdog", "fatal", "ready",
					  "handover", "stop-ack";

			power-domains = <&rpmpd MSM8953_VDDCX>,
					<&rpmpd MSM8953_VDDMX>,
					<&rpmpd MSM8953_VDDMD>;
			power-domain-names = "cx", "mx","mss";

			clocks = <&gcc GCC_MSS_CFG_AHB_CLK>,
				 <&gcc GCC_MSS_Q6_BIMC_AXI_CLK>,
				 <&gcc GCC_BOOT_ROM_AHB_CLK>,
				 <&rpmcc RPM_SMD_XO_CLK_SRC>;
			clock-names = "iface", "bus", "mem", "xo";

			qcom,smem-states = <&smp2p_modem_out 0>;
			qcom,smem-state-names = "stop";

			resets = <&gcc GCC_MSS_BCR>;
			reset-names = "mss_restart";

			qcom,halt-regs = <&tcsr 0x18000 0x19000 0x1a000>;

			status = "disabled";

			mba {
				memory-region = <&mba_mem>;
			};

			mpss {
				memory-region = <&mpss_mem>;
			};

			smd-edge {
				interrupts = <GIC_SPI 25 IRQ_TYPE_EDGE_RISING>;

				qcom,smd-edge = <0>;
				qcom,ipc = <&apcs 8 12>;
				qcom,remote-pid = <1>;

				label = "modem";
			};
		};

		usb3: usb@70f8800 {
			compatible = "qcom,msm8953-dwc3", "qcom,dwc3";
			reg = <0x070f8800 0x400>;
			#address-cells = <1>;
			#size-cells = <1>;
			ranges;

			interrupts = <GIC_SPI 136 IRQ_TYPE_LEVEL_HIGH>,
				     <GIC_SPI 220 IRQ_TYPE_LEVEL_HIGH>;
			interrupt-names = "hs_phy_irq", "ss_phy_irq";

			clocks = <&gcc GCC_USB_PHY_CFG_AHB_CLK>,
				 <&gcc GCC_USB30_MASTER_CLK>,
				 <&gcc GCC_PCNOC_USB3_AXI_CLK>,
				 <&gcc GCC_USB30_SLEEP_CLK>,
				 <&gcc GCC_USB30_MOCK_UTMI_CLK>;
			clock-names = "cfg_noc",
				      "core",
				      "iface",
				      "sleep",
				      "mock_utmi";

			assigned-clocks = <&gcc GCC_USB30_MOCK_UTMI_CLK>,
					  <&gcc GCC_USB30_MASTER_CLK>;
			assigned-clock-rates = <19200000>, <133330000>;

			interconnects = <&pcnoc MAS_USB3 &bimc SLV_EBI>,
					<&bimc MAS_APPS_PROC &pcnoc SLV_USB3>;
			interconnect-names = "usb-ddr", "apps-usb";

			power-domains = <&gcc USB30_GDSC>;

			qcom,select-utmi-as-pipe-clk;

			status = "disabled";

			usb3_dwc3: usb@7000000 {
				compatible = "snps,dwc3";
				reg = <0x07000000 0xcc00>;
				interrupts = <GIC_SPI 140 IRQ_TYPE_LEVEL_HIGH>;
				phys = <&hsusb_phy>;
				phy-names = "usb2-phy";

				snps,usb2-gadget-lpm-disable;
				snps,dis-u1-entry-quirk;
				snps,dis-u2-entry-quirk;
				snps,is-utmi-l1-suspend;
				snps,hird-threshold = /bits/ 8 <0x00>;

				maximum-speed = "high-speed";
			};
		};

		sdhc_1: mmc@7824900 {
			compatible = "qcom,msm8953-sdhci", "qcom,sdhci-msm-v4";

			reg = <0x07824900 0x500>, <0x07824000 0x800>;
			reg-names = "hc", "core";

			interrupts = <GIC_SPI 123 IRQ_TYPE_LEVEL_HIGH>,
				     <GIC_SPI 138 IRQ_TYPE_LEVEL_HIGH>;
			interrupt-names = "hc_irq", "pwr_irq";

			clocks = <&gcc GCC_SDCC1_AHB_CLK>,
				 <&gcc GCC_SDCC1_APPS_CLK>,
				 <&rpmcc RPM_SMD_XO_CLK_SRC>;
			clock-names = "iface", "core", "xo";

			interconnects = <&pcnoc MAS_SDCC_1 &bimc SLV_EBI>,
					<&bimc MAS_APPS_PROC &pcnoc SLV_SDCC_1>;

			power-domains = <&rpmpd MSM8953_VDDCX>;
			operating-points-v2 = <&sdhc1_opp_table>;

			pinctrl-names = "default", "sleep";
			pinctrl-0 = <&sdc1_clk_on &sdc1_cmd_on &sdc1_data_on &sdc1_rclk_on>;
			pinctrl-1 = <&sdc1_clk_off &sdc1_cmd_off &sdc1_data_off &sdc1_rclk_off>;

			mmc-hs400-1_8v;
			mmc-hs200-1_8v;
			mmc-ddr-1_8v;
			bus-width = <8>;
			non-removable;

			status = "disabled";

			sdhc1_opp_table: opp-table-sdhc1 {
				compatible = "operating-points-v2";

				opp-25000000 {
					opp-hz = /bits/ 64 <25000000>;
					opp-peak-kBps = <200000>, <100000>;
					opp-avg-kBps = <65360>, <32768>;
					required-opps = <&rpmpd_opp_low_svs>;
				};

				opp-50000000 {
					opp-hz = /bits/ 64 <50000000>;
					opp-peak-kBps = <400000>, <200000>;
					opp-avg-kBps = <130718>, <65360>;
					required-opps = <&rpmpd_opp_svs>;
				};

				opp-100000000 {
					opp-hz = /bits/ 64 <100000000>;
					opp-peak-kBps = <400000>, <400000>;
					opp-avg-kBps = <130718>, <65360>;
					required-opps = <&rpmpd_opp_svs>;
				};

				opp-192000000 {
					opp-hz = /bits/ 64 <192000000>;
					opp-peak-kBps = <800000>, <600000>;
					opp-avg-kBps = <261438>, <130718>;
					required-opps = <&rpmpd_opp_nom>;
				};

				opp-384000000 {
					opp-hz = /bits/ 64 <384000000>;
					opp-peak-kBps = <800000>, <800000>;
					opp-avg-kBps = <261438>, <300000>;
					required-opps = <&rpmpd_opp_nom>;
				};
			};
		};

		sdhc_2: mmc@7864900 {
			compatible = "qcom,msm8953-sdhci", "qcom,sdhci-msm-v4";

			reg = <0x07864900 0x500>, <0x07864000 0x800>;
			reg-names = "hc", "core";

			interrupts = <GIC_SPI 125 IRQ_TYPE_LEVEL_HIGH>,
				     <GIC_SPI 221 IRQ_TYPE_LEVEL_HIGH>;
			interrupt-names = "hc_irq", "pwr_irq";

			clocks = <&gcc GCC_SDCC2_AHB_CLK>,
				 <&gcc GCC_SDCC2_APPS_CLK>,
				 <&rpmcc RPM_SMD_XO_CLK_SRC>;
			clock-names = "iface", "core", "xo";

			interconnects = <&pcnoc MAS_SDCC_2 &bimc SLV_EBI>,
					<&bimc MAS_APPS_PROC &pcnoc SLV_SDCC_2>;

			power-domains = <&rpmpd MSM8953_VDDCX>;
			operating-points-v2 = <&sdhc2_opp_table>;

			pinctrl-names = "default", "sleep";
			pinctrl-0 = <&sdc2_clk_on &sdc2_cmd_on &sdc2_data_on>;
			pinctrl-1 = <&sdc2_clk_off &sdc2_cmd_off &sdc2_data_off>;

			bus-width = <4>;

			status = "disabled";

			sdhc2_opp_table: opp-table-sdhc2 {
				compatible = "operating-points-v2";

				opp-25000000 {
					opp-hz = /bits/ 64 <25000000>;
					opp-peak-kBps = <200000>, <100000>;
					opp-avg-kBps = <65360>, <32768>;
					required-opps = <&rpmpd_opp_low_svs>;
				};

				opp-50000000 {
					opp-hz = /bits/ 64 <50000000>;
					opp-peak-kBps = <400000>, <400000>;
					opp-avg-kBps = <130718>, <65360>;
					required-opps = <&rpmpd_opp_svs>;
				};

				opp-100000000 {
					opp-hz = /bits/ 64 <100000000>;
					opp-peak-kBps = <800000>, <400000>;
					opp-avg-kBps = <130718>, <130718>;
					required-opps = <&rpmpd_opp_svs>;
				};

				opp-177770000 {
					opp-hz = /bits/ 64 <177770000>;
					opp-peak-kBps = <600000>, <600000>;
					opp-avg-kBps = <261438>, <130718>;
					required-opps = <&rpmpd_opp_nom>;
				};

				opp-200000000 {
					opp-hz = /bits/ 64 <200000000>;
					opp-peak-kBps = <800000>, <800000>;
					opp-avg-kBps = <261438>, <130718>;
					required-opps = <&rpmpd_opp_nom>;
				};
			};
		};

		blsp1_dma: dma-controller@7884000 {
			compatible = "qcom,bam-v1.7.0";
			reg = <0x07884000 0x1f000>;
			interrupts = <GIC_SPI 238 IRQ_TYPE_LEVEL_HIGH>;
			clocks = <&gcc GCC_BLSP1_AHB_CLK>;
			clock-names = "bam_clk";
			num-channels = <12>;
			#dma-cells = <1>;
			qcom,ee = <0>;
			qcom,num-ees = <4>;
			qcom,controlled-remotely;
		};

		uart_0: serial@78af000 {
			compatible = "qcom,msm-uartdm-v1.4", "qcom,msm-uartdm";
			reg = <0x078af000 0x200>;
			interrupts = <GIC_SPI 107 IRQ_TYPE_LEVEL_HIGH>;
			clocks = <&gcc GCC_BLSP1_UART1_APPS_CLK>,
				 <&gcc GCC_BLSP1_AHB_CLK>;
			clock-names = "core", "iface";

			status = "disabled";
		};

		i2c_1: i2c@78b5000 {
			compatible = "qcom,i2c-qup-v2.2.1";
			reg = <0x078b5000 0x600>;
			interrupts = <GIC_SPI 95 IRQ_TYPE_LEVEL_HIGH>;
			clock-names = "core", "iface";
			clocks = <&gcc GCC_BLSP1_QUP1_I2C_APPS_CLK>,
				 <&gcc GCC_BLSP1_AHB_CLK>;
			dmas = <&blsp1_dma 4>, <&blsp1_dma 5>;
			dma-names = "tx", "rx";

			pinctrl-names = "default", "sleep";
			pinctrl-0 = <&i2c_1_default>;
			pinctrl-1 = <&i2c_1_sleep>;

			#address-cells = <1>;
			#size-cells = <0>;

			status = "disabled";
		};

		i2c_2: i2c@78b6000 {
			compatible = "qcom,i2c-qup-v2.2.1";
			reg = <0x078b6000 0x600>;
			interrupts = <GIC_SPI 96 IRQ_TYPE_LEVEL_HIGH>;
			clock-names = "core", "iface";
			clocks = <&gcc GCC_BLSP1_QUP2_I2C_APPS_CLK>,
				 <&gcc GCC_BLSP1_AHB_CLK>;
			dmas = <&blsp1_dma 6>, <&blsp1_dma 7>;
			dma-names = "tx", "rx";

			pinctrl-names = "default", "sleep";
			pinctrl-0 = <&i2c_2_default>;
			pinctrl-1 = <&i2c_2_sleep>;

			#address-cells = <1>;
			#size-cells = <0>;

			status = "disabled";
		};

		i2c_3: i2c@78b7000 {
			compatible = "qcom,i2c-qup-v2.2.1";
			reg = <0x078b7000 0x600>;
			interrupts = <GIC_SPI 97 IRQ_TYPE_LEVEL_HIGH>;
			clock-names = "core", "iface";
			clocks = <&gcc GCC_BLSP1_QUP3_I2C_APPS_CLK>,
				 <&gcc GCC_BLSP1_AHB_CLK>;
			dmas = <&blsp1_dma 8>, <&blsp1_dma 9>;
			dma-names = "tx", "rx";

			pinctrl-names = "default", "sleep";
			pinctrl-0 = <&i2c_3_default>;
			pinctrl-1 = <&i2c_3_sleep>;

			#address-cells = <1>;
			#size-cells = <0>;

			status = "disabled";
		};

		spi_3: spi@78b7000 {
			compatible = "qcom,spi-qup-v2.2.1";
			reg = <0x078b7000 0x600>;
			interrupts = <GIC_SPI 97 IRQ_TYPE_LEVEL_HIGH>;
			clock-names = "core", "iface";
			clocks = <&gcc GCC_BLSP1_QUP3_I2C_APPS_CLK>,
				 <&gcc GCC_BLSP1_AHB_CLK>;
			dmas = <&blsp1_dma 8>, <&blsp1_dma 9>;
			dma-names = "tx", "rx";

			pinctrl-names = "default", "sleep";
			pinctrl-0 = <&spi_3_default>;
			pinctrl-1 = <&spi_3_sleep>;

			#address-cells = <1>;
			#size-cells = <0>;

			status = "disabled";
		};

		i2c_4: i2c@78b8000 {
			compatible = "qcom,i2c-qup-v2.2.1";
			reg = <0x078b8000 0x600>;
			interrupts = <GIC_SPI 98 IRQ_TYPE_LEVEL_HIGH>;
			clock-names = "core", "iface";
			clocks = <&gcc GCC_BLSP1_QUP4_I2C_APPS_CLK>,
				 <&gcc GCC_BLSP1_AHB_CLK>;
			dmas = <&blsp2_dma 10>, <&blsp2_dma 11>;
			dma-names = "tx", "rx";

			pinctrl-names = "default", "sleep";
			pinctrl-0 = <&i2c_4_default>;
			pinctrl-1 = <&i2c_4_sleep>;

			#address-cells = <1>;
			#size-cells = <0>;

			status = "disabled";
		};

		blsp2_dma: dma-controller@7ac4000 {
			compatible = "qcom,bam-v1.7.0";
			reg = <0x07ac4000 0x1f000>;
			interrupts = <GIC_SPI 239 IRQ_TYPE_LEVEL_HIGH>;
			clocks = <&gcc GCC_BLSP2_AHB_CLK>;
			clock-names = "bam_clk";
			num-channels = <12>;
			#dma-cells = <1>;
			qcom,ee = <0>;
			qcom,num-ees = <4>;
			qcom,controlled-remotely;
		};

		i2c_5: i2c@7af5000 {
			compatible = "qcom,i2c-qup-v2.2.1";
			reg = <0x07af5000 0x600>;
			interrupts = <GIC_SPI 299 IRQ_TYPE_LEVEL_HIGH>;
			clock-names = "core", "iface";
			clocks = <&gcc GCC_BLSP2_QUP1_I2C_APPS_CLK>,
				 <&gcc GCC_BLSP2_AHB_CLK>;
			dmas = <&blsp2_dma 4>, <&blsp2_dma 5>;
			dma-names = "tx", "rx";

			pinctrl-names = "default", "sleep";
			pinctrl-0 = <&i2c_5_default>;
			pinctrl-1 = <&i2c_5_sleep>;

			#address-cells = <1>;
			#size-cells = <0>;

			status = "disabled";
		};

		spi_5: spi@7af5000 {
			compatible = "qcom,spi-qup-v2.2.1";
			reg = <0x07af5000 0x600>;
			interrupts = <GIC_SPI 299 IRQ_TYPE_LEVEL_HIGH>;
			clock-names = "core", "iface";
			clocks = <&gcc GCC_BLSP2_QUP1_I2C_APPS_CLK>,
				<&gcc GCC_BLSP2_AHB_CLK>;
			dmas = <&blsp2_dma 4>, <&blsp2_dma 5>;
			dma-names = "tx", "rx";

			pinctrl-names = "default", "sleep";
			pinctrl-0 = <&spi_5_default>;
			pinctrl-1 = <&spi_5_sleep>;

			#address-cells = <1>;
			#size-cells = <0>;

			status = "disabled";
		};

		i2c_6: i2c@7af6000 {
			compatible = "qcom,i2c-qup-v2.2.1";
			reg = <0x07af6000 0x600>;
			interrupts = <GIC_SPI 300 IRQ_TYPE_LEVEL_HIGH>;
			clock-names = "core", "iface";
			clocks = <&gcc GCC_BLSP2_QUP2_I2C_APPS_CLK>,
				 <&gcc GCC_BLSP2_AHB_CLK>;
			dmas = <&blsp2_dma 6>, <&blsp2_dma 7>;
			dma-names = "tx", "rx";

			pinctrl-names = "default", "sleep";
			pinctrl-0 = <&i2c_6_default>;
			pinctrl-1 = <&i2c_6_sleep>;

			#address-cells = <1>;
			#size-cells = <0>;

			status = "disabled";
		};

		spi_6: spi@7af6000 {
			compatible = "qcom,spi-qup-v2.2.1";
			reg = <0x07af6000 0x600>;
			interrupts = <GIC_SPI 300 IRQ_TYPE_LEVEL_HIGH>;
			clock-names = "core", "iface";
			clocks = <&gcc GCC_BLSP2_QUP2_I2C_APPS_CLK>,
				 <&gcc GCC_BLSP2_AHB_CLK>;
			dmas = <&blsp2_dma 6>, <&blsp2_dma 7>;
			dma-names = "tx", "rx";

			pinctrl-names = "default", "sleep";
			pinctrl-0 = <&spi_6_default>;
			pinctrl-1 = <&spi_6_sleep>;

			#address-cells = <1>;
			#size-cells = <0>;

			status = "disabled";
		};

		i2c_7: i2c@7af7000 {
			compatible = "qcom,i2c-qup-v2.2.1";
			reg = <0x07af7000 0x600>;
			interrupts = <GIC_SPI 301 IRQ_TYPE_LEVEL_HIGH>;
			clock-names = "core", "iface";
			clocks = <&gcc GCC_BLSP2_QUP3_I2C_APPS_CLK>,
				 <&gcc GCC_BLSP2_AHB_CLK>;
			dmas = <&blsp2_dma 8>, <&blsp2_dma 9>;
			dma-names = "tx", "rx";

			pinctrl-names = "default", "sleep";
			pinctrl-0 = <&i2c_7_default>;
			pinctrl-1 = <&i2c_7_sleep>;

			#address-cells = <1>;
			#size-cells = <0>;

			status = "disabled";
		};

		i2c_8: i2c@7af8000 {
			compatible = "qcom,i2c-qup-v2.2.1";
			reg = <0x07af8000 0x600>;
			interrupts = <GIC_SPI 302 IRQ_TYPE_LEVEL_HIGH>;
			clock-names = "core", "iface";
			clocks = <&gcc GCC_BLSP2_QUP4_I2C_APPS_CLK>,
				 <&gcc GCC_BLSP2_AHB_CLK>;
			dmas = <&blsp2_dma 10>, <&blsp2_dma 11>;
			dma-names = "tx", "rx";

			pinctrl-names = "default", "sleep";
			pinctrl-0 = <&i2c_8_default>;
			pinctrl-1 = <&i2c_8_sleep>;

			#address-cells = <1>;
			#size-cells = <0>;

			status = "disabled";
		};

		wcnss: remoteproc@a204000 {
			compatible = "qcom,pronto-v3-pil", "qcom,pronto";
			reg = <0x0a204000 0x2000>, <0x0a202000 0x1000>, <0x0a21b000 0x3000>;
			reg-names = "ccu", "dxe", "pmu";

			memory-region = <&wcnss_fw_mem>;

			interrupts-extended = <&intc GIC_SPI 149 IRQ_TYPE_EDGE_RISING>,
					      <&smp2p_wcnss_in 0 IRQ_TYPE_EDGE_RISING>,
					      <&smp2p_wcnss_in 1 IRQ_TYPE_EDGE_RISING>,
					      <&smp2p_wcnss_in 2 IRQ_TYPE_EDGE_RISING>,
					      <&smp2p_wcnss_in 3 IRQ_TYPE_EDGE_RISING>;
			interrupt-names = "wdog", "fatal", "ready", "handover", "stop-ack";

			power-domains = <&rpmpd MSM8953_VDDCX>,
					<&rpmpd MSM8953_VDDMX>;
			power-domain-names = "cx", "mx";

			qcom,smem-states = <&smp2p_wcnss_out 0>;
			qcom,smem-state-names = "stop";

			pinctrl-names = "default";
			pinctrl-0 = <&wcnss_pin_a>;

			status = "disabled";

			wcnss_iris: iris {
				/* Separate chip, compatible is board-specific */
				clocks = <&rpmcc RPM_SMD_RF_CLK2>;
				clock-names = "xo";
			};

			smd-edge {
				interrupts = <GIC_SPI 142 IRQ_TYPE_EDGE_RISING>;

				qcom,ipc = <&apcs 8 17>;
				qcom,smd-edge = <6>;
				qcom,remote-pid = <4>;

				label = "pronto";

				wcnss_ctrl: wcnss {
					compatible = "qcom,wcnss";
					qcom,smd-channels = "WCNSS_CTRL";

					qcom,mmio = <&wcnss>;

					wcnss_bt: bluetooth {
						compatible = "qcom,wcnss-bt";
					};

					wcnss_wifi: wifi {
						compatible = "qcom,wcnss-wlan";

						interrupts = <GIC_SPI 145 IRQ_TYPE_LEVEL_HIGH>,
							     <GIC_SPI 146 IRQ_TYPE_LEVEL_HIGH>;
						interrupt-names = "tx", "rx";

						qcom,smem-states = <&apps_smsm 10>, <&apps_smsm 9>;
						qcom,smem-state-names = "tx-enable",
									"tx-rings-empty";
					};
				};
			};
		};

		intc: interrupt-controller@b000000 {
			compatible = "qcom,msm-qgic2";
			interrupt-controller;
			#interrupt-cells = <3>;
			reg = <0x0b000000 0x1000>, <0x0b002000 0x1000>;
		};

		apcs: mailbox@b011000 {
			compatible = "qcom,msm8953-apcs-kpss-global", "syscon";
			reg = <0x0b011000 0x1000>;
			#mbox-cells = <1>;
		};

		apcc_c1_mux: clock-controller@b011050 {
			compatible = "qcom,cpu-mux-div-clock";
			reg = <0xb011050 0x10>;
			clocks = <&apcc_pll>, <&gcc GPLL0_EARLY>;
			qcom,mux-values = <5>, <4>;
			qcom,safe-div = <3>;
			clock-output-names = "apcc-c1-mux";
			assigned-clocks = <&apcc_c1_mux>;
			assigned-clock-parents = <&apcc_pll>;
			assigned-clock-rates = <883200000>;
			#clock-cells = <0>;
		};

		cpr: power-controller@b018000 {
			compatible = "qcom,msm8953-cpr4";

			nvmem-cells = <&cpr_efuse_quot_offset3>,
				      <&cpr_efuse_quot_offset2>,
				      <&cpr_efuse_quot_offset1>,
				      <&cpr_efuse_init_voltage4>,
				      <&cpr_efuse_init_voltage3>,
				      <&cpr_efuse_init_voltage2>,
				      <&cpr_efuse_init_voltage1>,
				      <&cpr_efuse_quot4>,
				      <&cpr_efuse_quot3>,
				      <&cpr_efuse_quot2>,
				      <&cpr_efuse_quot1>,
				      <&cpr_efuse_ring4>,
				      <&cpr_efuse_ring3>,
				      <&cpr_efuse_ring2>,
				      <&cpr_efuse_ring1>,
				      <&cpr_efuse_revision>,
				      <&cpu_speed_bin>;
			nvmem-cell-names = "cpr_thread0_quotient_offset2",
					   "cpr_thread0_quotient_offset3",
					   "cpr_thread0_quotient_offset4",
					   "cpr_thread0_init_voltage1",
					   "cpr_thread0_init_voltage2",
					   "cpr_thread0_init_voltage3",
					   "cpr_thread0_init_voltage4",
					   "cpr_thread0_quotient1",
					   "cpr_thread0_quotient2",
					   "cpr_thread0_quotient3",
					   "cpr_thread0_quotient4",
					   "cpr_thread0_ring_osc1",
					   "cpr_thread0_ring_osc2",
					   "cpr_thread0_ring_osc3",
					   "cpr_thread0_ring_osc4",
					   "cpr_fuse_revision",
					   "cpr_speed_bin";

			reg = <0x0b018000 0x4000>;
			reg-names = "cpr-iomem";

			interrupts = <GIC_SPI 15 IRQ_TYPE_EDGE_RISING>;

			clocks = <&xo_board>;
			clock-names = "ref";

			acc-syscon = <&apc_mem_acc>;
			apm-syscon = <&apm>;

			#power-domain-cells = <1>;
			operating-points-v2 = <&cpr_opp_table>;

			cpr_opp_table: cpr-opp-table {
				compatible = "operating-points-v2-qcom-level";

				cpr_opp1: opp1 {
					opp-level = <1>;
				};
				cpr_opp2: opp2 {
					opp-level = <2>;
				};
				cpr_opp3: opp3 {
					opp-level = <3>;
				};
				cpr_opp4: opp4 {
					opp-level = <4>;
				};
				cpr_opp5: opp5 {
					opp-level = <5>;
				};
				cpr_opp6: opp6 {
					opp-level = <6>;
				};
				cpr_opp7: opp7 {
					opp-level = <7>;
				};
				cpr_opp8: opp8 {
					opp-level = <8>;
				};
				cpr_opp9: opp9 {
					opp-level = <9>;
				};
				cpr_opp10: opp10 {
					opp-level = <10>;
				};
			};
		};

		apcc_pll: clock-controller@b106000 {
			compatible = "qcom,msm8953-apcc-alpha-pll";
			reg = <0xb116000 0x40>;
			qcom,vco-ranges = <0 652800000 2208000000>;
			clocks = <&xo_board>;
			clock-output-names = "apcc-pll";
			assigned-clocks = <&apcc_pll>;
			assigned-clock-rates = <883200000>;
			#clock-cells = <0>;
		};

		apm: syscon@b111000 {
			compatible = "syscon";
			reg = <0xb111000 0x1000>;
		};

		apcc_c0_mux: clock-controller@b111050 {
			compatible = "qcom,cpu-mux-div-clock";
			reg = <0xb111050 0x10>;
			clocks = <&apcc_pll>, <&gcc GPLL0_EARLY>;
			qcom,mux-values = <5>, <4>;
			qcom,safe-div = <3>;
			clock-output-names = "apcc-c0-mux";
			assigned-clocks = <&apcc_c0_mux>;
			assigned-clock-parents = <&apcc_pll>;
			assigned-clock-rates = <883200000>;
			#clock-cells = <0>;
		};


		apcc_cci_mux: clock-controller@b1d1050 {
			compatible = "qcom,cpu-mux-div-clock";
			reg = <0xb1d1050 0x10>;
			clocks = <&apcc_pll>, <&gcc GPLL0_EARLY>;
			qcom,mux-values = <5>, <4>;
			qcom,safe-div = <5>;
			clock-output-names = "apcc-cci-mux";
			assigned-clocks = <&apcc_cci_mux>;
			assigned-clock-parents = <&apcc_pll>;
			assigned-clock-rates = <(883200000 * 2 / 5)>;
			#clock-cells = <0>;
		};

		timer@b120000 {
			compatible = "arm,armv7-timer-mem";
			reg = <0x0b120000 0x1000>;
			#address-cells = <0x01>;
			#size-cells = <0x01>;
			ranges;

			frame@b121000 {
				frame-number = <0>;
				interrupts = <GIC_SPI 8 IRQ_TYPE_LEVEL_HIGH>,
					     <GIC_SPI 7 IRQ_TYPE_LEVEL_HIGH>;
				reg = <0x0b121000 0x1000>,
				      <0x0b122000 0x1000>;
			};

			frame@b123000 {
				frame-number = <1>;
				interrupts = <GIC_SPI 9 IRQ_TYPE_LEVEL_HIGH>;
				reg = <0x0b123000 0x1000>;
				status = "disabled";
			};

			frame@b124000 {
				frame-number = <2>;
				interrupts = <GIC_SPI 10 IRQ_TYPE_LEVEL_HIGH>;
				reg = <0x0b124000 0x1000>;
				status = "disabled";
			};

			frame@b125000 {
				frame-number = <3>;
				interrupts = <GIC_SPI 11 IRQ_TYPE_LEVEL_HIGH>;
				reg = <0x0b125000 0x1000>;
				status = "disabled";
			};

			frame@b126000 {
				frame-number = <4>;
				interrupts = <GIC_SPI 12 IRQ_TYPE_LEVEL_HIGH>;
				reg = <0x0b126000 0x1000>;
				status = "disabled";
			};

			frame@b127000 {
				frame-number = <5>;
				interrupts = <GIC_SPI 13 IRQ_TYPE_LEVEL_HIGH>;
				reg = <0x0b127000 0x1000>;
				status = "disabled";
			};

			frame@b128000 {
				frame-number = <6>;
				interrupts = <GIC_SPI 14 IRQ_TYPE_LEVEL_HIGH>;
				reg = <0x0b128000 0x1000>;
				status = "disabled";
			};
		};

		saw4: syscon@b1d2000 {
			compatible = "syscon";
			reg = <0xb1d2000 0x1000>;
		};

		sound_card: sound-card@c051000 {
			compatible = "qcom,msm8953-qdsp6-sndcard";
			reg = <0xc051000 0x4>,
			      <0xc051004 0x4>,
			      <0xc055000 0x4>,
			      <0xc052000 0x4>;
			reg-names = "mic-iomux",
				    "spkr-iomux",
				    "pri-iomux",
				    "quin-iomux";

			audio-routing =
#if 0
				"AMIC1", "MIC BIAS External1",
				"AMIC2", "MIC BIAS External2",
				"AMIC3", "MIC BIAS External1",
#endif
				"MM_DL1", "MultiMedia1 Playback",
				"MM_DL3", "MultiMedia3 Playback",
				"MM_DL4", "MultiMedia4 Playback",
				"MultiMedia2 Capture", "MM_UL2";

			status = "disabled";

			mm1-dai-link {
				link-name = "MultiMedia1";
				cpu {
					sound-dai = <&q6asmdai MSM_FRONTEND_DAI_MULTIMEDIA1>;
				};
			};

			mm2-dai-link {
				link-name = "MultiMedia2";
				cpu {
					sound-dai = <&q6asmdai MSM_FRONTEND_DAI_MULTIMEDIA2>;
				};
			};

			mm3-dai-link {
				link-name = "MultiMedia3";
				cpu {
					sound-dai = <&q6asmdai MSM_FRONTEND_DAI_MULTIMEDIA3>;
				};
			};

			mm4-dai-link {
				link-name = "MultiMedia4";
				cpu {
					sound-dai = <&q6asmdai MSM_FRONTEND_DAI_MULTIMEDIA4>;
				};
			};

			cs-voice-dai-link {
				link-name = "CS-Voice";
				cpu {
					sound-dai = <&q6voicedai CS_VOICE>;
				};
			};

#if 0
			primary-mi2s-dai-link {
				link-name = "Primary MI2S";
				cpu {
					sound-dai = <&q6afedai PRIMARY_MI2S_RX>;
				};

				platform {
					sound-dai = <&q6routing>;
				};

				codec {
					sound-dai = <&lpass_codec 0>, <&wcd_codec 0>;
				};
			};

			tertiary-mi2s-dai-link {
				link-name = "Tertiary MI2S";
				cpu {
					sound-dai = <&q6afedai TERTIARY_MI2S_TX>;
				};

				platform {
					sound-dai = <&q6routing>;
				};

				codec {
					sound-dai = <&lpass_codec 1>, <&wcd_codec 1>;
				};
			};
#endif
		};

		lpass_codec: codec@c0f0000 {
			compatible = "qcom,msm8916-wcd-digital-codec";
			reg = <0xc0f0000 0x400>;
			#sound-dai-cells = <1>;

			clocks = <&q6afecc LPASS_CLK_ID_INTERNAL_DIGITAL_CODEC_CORE
					   LPASS_CLK_ATTRIBUTE_COUPLE_NO>,
				 <&xo_board>;
			clock-names = "mclk", "ahbix-clk";
		};

		lpass: remoteproc@c200000 {
			compatible = "qcom,msm8953-adsp-pil";
			reg = <0x0c200000 0x100>;

			interrupts-extended = <&intc 0 293 IRQ_TYPE_EDGE_RISING>,
					      <&smp2p_adsp_in 0 IRQ_TYPE_EDGE_RISING>,
					      <&smp2p_adsp_in 1 IRQ_TYPE_EDGE_RISING>,
					      <&smp2p_adsp_in 2 IRQ_TYPE_EDGE_RISING>,
					      <&smp2p_adsp_in 3 IRQ_TYPE_EDGE_RISING>;
			interrupt-names = "wdog", "fatal", "ready",
					  "handover", "stop-ack";
			clocks = <&rpmcc RPM_SMD_XO_CLK_SRC>;
			clock-names = "xo";

			power-domains = <&rpmpd MSM8953_VDDCX>;
			power-domain-names = "cx";

			memory-region = <&adsp_fw_mem>;

			qcom,smem-states = <&smp2p_adsp_out 0>;
			qcom,smem-state-names = "stop";

			status = "disabled";

			smd-edge {
				interrupts = <GIC_SPI 289 IRQ_TYPE_EDGE_RISING>;

				label = "lpass";
				mboxes = <&apcs 8>;
				qcom,smd-edge = <1>;
				qcom,remote-pid = <2>;

				apr {
					compatible = "qcom,apr-v2";
					qcom,smd-channels = "apr_audio_svc";
					qcom,apr-domain = <APR_DOMAIN_ADSP>;
					#address-cells = <1>;
					#size-cells = <0>;

					q6core: service@3 {
						reg = <APR_SVC_ADSP_CORE>;
						compatible = "qcom,q6core";
					};

					q6afe: service@4 {
						compatible = "qcom,q6afe";
						reg = <APR_SVC_AFE>;
						q6afedai: dais {
							compatible = "qcom,q6afe-dais";
							#address-cells = <1>;
							#size-cells = <0>;
							#sound-dai-cells = <1>;

							dai@16 {
								reg = <PRIMARY_MI2S_RX>;
								qcom,sd-lines = <0 1>;
							};
							dai@20 {
								reg = <TERTIARY_MI2S_TX>;
								qcom,sd-lines = <0 1>;
							};
							dai@127 {
								reg = <QUINARY_MI2S_RX>;
								qcom,sd-lines = <0>;
							};
						};

						q6afecc: clock-controller {
							compatible = "qcom,q6afe-clocks";
							#clock-cells = <2>;
						};
					};

					q6asm: service@7 {
						compatible = "qcom,q6asm";
						reg = <APR_SVC_ASM>;
						q6asmdai: dais {
							compatible = "qcom,q6asm-dais";
							#address-cells = <1>;
							#size-cells = <0>;
							#sound-dai-cells = <1>;

							dai@0 {
								reg = <0>;
								direction = <Q6ASM_DAI_RX>;
							};
							dai@1 {
								reg = <1>;
								direction = <Q6ASM_DAI_TX>;
							};
							dai@2 {
								reg = <2>;
								direction = <Q6ASM_DAI_RX>;
							};
							dai@3 {
								reg = <3>;
								direction = <Q6ASM_DAI_RX>;
								is-compress-dai;
							};
						};
					};

					q6adm: service@8 {
						compatible = "qcom,q6adm";
						reg = <APR_SVC_ADM>;
						q6routing: routing {
							compatible = "qcom,q6adm-routing";
							#sound-dai-cells = <0>;
						};
					};

					q6mvm: service@9 {
						compatible = "qcom,q6mvm";
						reg = <APR_SVC_ADSP_MVM>;

						q6voicedai: dais {
							compatible = "qcom,q6voice-dais";
							#sound-dai-cells = <0>;
						};
					};

					q6cvs: service@a {
						compatible = "qcom,q6cvs";
						reg = <APR_SVC_ADSP_CVS>;
					};

					q6cvp: service@b {
						compatible = "qcom,q6cvp";
						reg = <APR_SVC_ADSP_CVP>;
					};
				};
			};
		};
	};

	thermal-zones {
		cpu0-thermal {
			polling-delay-passive = <250>;
			polling-delay = <1000>;
			thermal-sensors = <&tsens0 9>;
			trips {
				cpu0_alert: trip-point0 {
					temperature = <80000>;
					hysteresis = <2000>;
					type = "passive";
				};
				cpu0_crit: crit {
					temperature = <100000>;
					hysteresis = <2000>;
					type = "critical";
				};
			};
			cooling-maps {
				map0 {
					trip = <&cpu0_alert>;
					cooling-device = <&CPU0 THERMAL_NO_LIMIT THERMAL_NO_LIMIT>;
				};
			};
		};
		cpu1-thermal {
			polling-delay-passive = <250>;
			polling-delay = <1000>;
			thermal-sensors = <&tsens0 10>;
			trips {
				cpu1_alert: trip-point0 {
					temperature = <80000>;
					hysteresis = <2000>;
					type = "passive";
				};
				cpu1_crit: crit {
					temperature = <100000>;
					hysteresis = <2000>;
					type = "critical";
				};
			};
			cooling-maps {
				map0 {
					trip = <&cpu1_alert>;
					cooling-device = <&CPU1 THERMAL_NO_LIMIT THERMAL_NO_LIMIT>;
				};
			};
		};
		cpu2-thermal {
			polling-delay-passive = <250>;
			polling-delay = <1000>;
			thermal-sensors = <&tsens0 11>;
			trips {
				cpu2_alert: trip-point0 {
					temperature = <80000>;
					hysteresis = <2000>;
					type = "passive";
				};
				cpu2_crit: crit {
					temperature = <100000>;
					hysteresis = <2000>;
					type = "critical";
				};
			};
			cooling-maps {
				map0 {
					trip = <&cpu2_alert>;
					cooling-device = <&CPU2 THERMAL_NO_LIMIT THERMAL_NO_LIMIT>;
				};
			};
		};
		cpu3-thermal {
			polling-delay-passive = <250>;
			polling-delay = <1000>;
			thermal-sensors = <&tsens0 12>;
			trips {
				cpu3_alert: trip-point0 {
					temperature = <80000>;
					hysteresis = <2000>;
					type = "passive";
				};
				cpu3_crit: crit {
					temperature = <100000>;
					hysteresis = <2000>;
					type = "critical";
				};
			};
			cooling-maps {
				map0 {
					trip = <&cpu3_alert>;
					cooling-device = <&CPU3 THERMAL_NO_LIMIT THERMAL_NO_LIMIT>;
				};
			};
		};
		cpu4-thermal {
			polling-delay-passive = <250>;
			polling-delay = <1000>;
			thermal-sensors = <&tsens0 4>;
			trips {
				cpu4_alert: trip-point0 {
					temperature = <80000>;
					hysteresis = <2000>;
					type = "passive";
				};
				cpu4_crit: crit {
					temperature = <100000>;
					hysteresis = <2000>;
					type = "critical";
				};
			};
			cooling-maps {
				map0 {
					trip = <&cpu4_alert>;
					cooling-device = <&CPU4 THERMAL_NO_LIMIT THERMAL_NO_LIMIT>;
				};
			};
		};
		cpu5-thermal {
			polling-delay-passive = <250>;
			polling-delay = <1000>;
			thermal-sensors = <&tsens0 5>;
			trips {
				cpu5_alert: trip-point0 {
					temperature = <80000>;
					hysteresis = <2000>;
					type = "passive";
				};
				cpu5_crit: crit {
					temperature = <100000>;
					hysteresis = <2000>;
					type = "critical";
				};
			};
			cooling-maps {
				map0 {
					trip = <&cpu5_alert>;
					cooling-device = <&CPU5 THERMAL_NO_LIMIT THERMAL_NO_LIMIT>;
				};
			};
		};
		cpu6-thermal {
			polling-delay-passive = <250>;
			polling-delay = <1000>;
			thermal-sensors = <&tsens0 6>;
			trips {
				cpu6_alert: trip-point0 {
					temperature = <80000>;
					hysteresis = <2000>;
					type = "passive";
				};
				cpu6_crit: crit {
					temperature = <100000>;
					hysteresis = <2000>;
					type = "critical";
				};
			};
			cooling-maps {
				map0 {
					trip = <&cpu6_alert>;
					cooling-device = <&CPU6 THERMAL_NO_LIMIT THERMAL_NO_LIMIT>;
				};
			};
		};
		cpu7-thermal {
			polling-delay-passive = <250>;
			polling-delay = <1000>;
			thermal-sensors = <&tsens0 7>;
			trips {
				cpu7_alert: trip-point0 {
					temperature = <80000>;
					hysteresis = <2000>;
					type = "passive";
				};
				cpu7_crit: crit {
					temperature = <100000>;
					hysteresis = <2000>;
					type = "critical";
				};
			};
			cooling-maps {
				map0 {
					trip = <&cpu7_alert>;
					cooling-device = <&CPU7 THERMAL_NO_LIMIT THERMAL_NO_LIMIT>;
				};
			};
		};
		gpu-thermal {
			polling-delay-passive = <250>;
			polling-delay = <1000>;
			thermal-sensors = <&tsens0 15>;
			trips {
				gpu_alert: trip-point@0 {
					temperature = <70000>;
					hysteresis = <2000>;
					type = "passive";
				};
				gpu_crit: crit {
					temperature = <90000>;
					hysteresis = <2000>;
					type = "critical";
				};
			};
			cooling-maps {
				map0 {
					trip = <&gpu_alert>;
					cooling-device = <&gpu THERMAL_NO_LIMIT THERMAL_NO_LIMIT>;
				};
			};
		};
	};

	timer {
		compatible = "arm,armv8-timer";
		interrupts = <GIC_PPI 2 (GIC_CPU_MASK_SIMPLE(8) | IRQ_TYPE_LEVEL_LOW)>,
			     <GIC_PPI 3 (GIC_CPU_MASK_SIMPLE(8) | IRQ_TYPE_LEVEL_LOW)>,
			     <GIC_PPI 4 (GIC_CPU_MASK_SIMPLE(8) | IRQ_TYPE_LEVEL_LOW)>,
			     <GIC_PPI 1 (GIC_CPU_MASK_SIMPLE(8) | IRQ_TYPE_LEVEL_LOW)>;
	};
};
